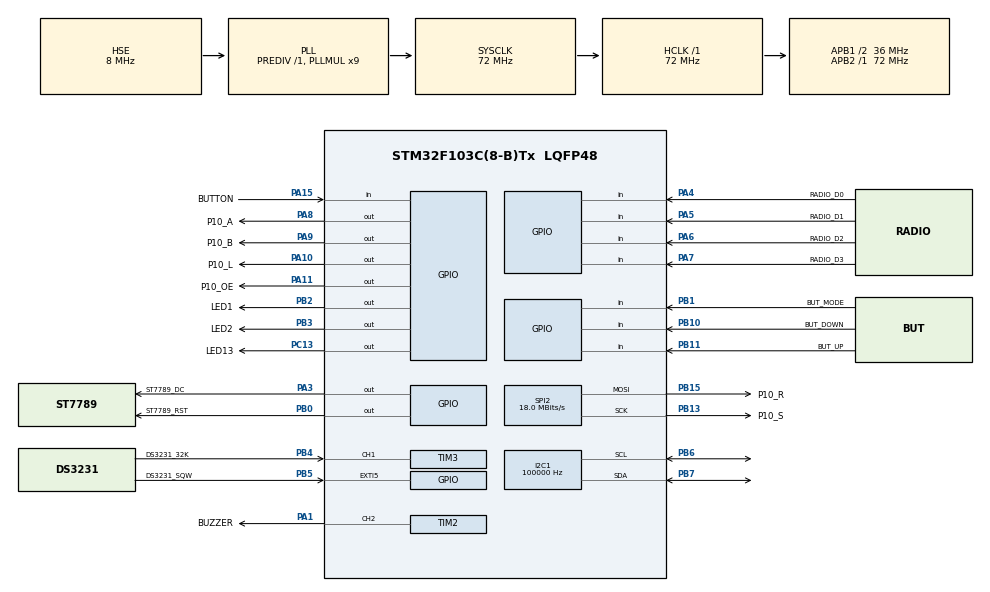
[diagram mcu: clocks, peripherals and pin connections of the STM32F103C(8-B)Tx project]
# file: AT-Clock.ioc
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Dma.Request0=SPI2_TX
Dma.SPI2_TX.0.Direction=DMA_MEMORY_TO_PERIPH
Dma.SPI2_TX.0.Instance=DMA1_Channel5
Dma.SPI2_TX.0.MemDataAlignment=DMA_MDATAALIGN_BYTE
Dma.SPI2_TX.0.MemInc=DMA_MINC_ENABLE
Dma.SPI2_TX.0.Mode=DMA_NORMAL
Dma.SPI2_TX.0.PeriphDataAlignment=DMA_PDATAALIGN_BYTE
Dma.SPI2_TX.0.PeriphInc=DMA_PINC_DISABLE
Dma.SPI2_TX.0.Priority=DMA_PRIORITY_LOW
I2C1.ClockSpeed=100000
I2C1.I2C_Mode=I2C_Standard
Mcu.Family=STM32F1
Mcu.Name=STM32F103C(8-B)Tx
Mcu.Package=LQFP48
NVIC.DMA1_Channel5_IRQn=true\:3\:0\:true\:false\:true\:false\:true\:true
NVIC.I2C1_ER_IRQn=true\:3\:0\:true\:false\:true\:true\:true\:true
NVIC.I2C1_EV_IRQn=true\:3\:0\:true\:false\:true\:true\:true\:true
NVIC.PriorityGroup=NVIC_PRIORITYGROUP_4
NVIC.TIM1_CC_IRQn=true\:2\:0\:true\:false\:true\:true\:true\:true
NVIC.TIM1_UP_IRQn=true\:2\:0\:true\:false\:true\:true\:true\:true
PA1.GPIO_Label=BUZZER
PA1.Signal=S_TIM2_CH2
PA10.GPIO_Label=P10_L
PA10.Signal=GPIO_Output
PA11.GPIO_Label=P10_OE
PA11.Signal=GPIO_Output
PA13.Mode=Serial_Wire
PA13.Signal=SYS_JTMS-SWDIO
PA14.Mode=Serial_Wire
PA14.Signal=SYS_JTCK-SWCLK
PA15.GPIO_Label=BUTTON
PA15.Signal=GPIO_Input
PA3.GPIO_Label=ST7789_DC
PA3.Signal=GPIO_Output
PA4.GPIO_Label=RADIO_D0
PA4.GPIO_PuPd=GPIO_PULLDOWN
PA4.Signal=GPIO_Input
PA5.GPIO_Label=RADIO_D1
PA5.GPIO_PuPd=GPIO_PULLDOWN
PA5.Signal=GPIO_Input
PA6.GPIO_Label=RADIO_D2
PA6.GPIO_PuPd=GPIO_PULLDOWN
PA6.Signal=GPIO_Input
PA7.GPIO_Label=RADIO_D3
PA7.GPIO_PuPd=GPIO_PULLDOWN
PA7.Signal=GPIO_Input
PA8.GPIO_Label=P10_A
PA8.Signal=GPIO_Output
PA9.GPIO_Label=P10_B
PA9.Signal=GPIO_Output
PB0.GPIO_Label=ST7789_RST
PB0.Signal=GPIO_Output
PB1.GPIO_Label=BUT_MODE
PB1.GPIO_PuPd=GPIO_PULLUP
PB1.Signal=GPIO_Input
PB10.GPIO_Label=BUT_DOWN
PB10.GPIO_PuPd=GPIO_PULLUP
PB10.Signal=GPIO_Input
PB11.GPIO_Label=BUT_UP
PB11.GPIO_PuPd=GPIO_PULLUP
PB11.Signal=GPIO_Input
PB13.GPIO_Label=P10_S
PB13.Mode=TX_Only_Simplex_Unidirect_Master
PB13.Signal=SPI2_SCK
PB15.GPIO_Label=P10_R
PB15.Mode=TX_Only_Simplex_Unidirect_Master
PB15.Signal=SPI2_MOSI
PB2.GPIO_Label=LED1
PB2.Signal=GPIO_Output
PB3.GPIO_Label=LED2
PB3.Signal=GPIO_Output
PB4.GPIO_Label=DS3231_32K
PB4.Signal=S_TIM3_CH1
PB5.GPIO_Label=DS3231_SQW
PB5.Signal=GPXTI5
PB6.GPIO_Pu=GPIO_PULLUP
PB6.Mode=I2C
PB6.Signal=I2C1_SCL
PB7.GPIO_Pu=GPIO_PULLUP
PB7.Mode=I2C
PB7.Signal=I2C1_SDA
PC13-TAMPER-RTC.GPIO_Label=LED13
PC13-TAMPER-RTC.Signal=GPIO_Output
PD0-OSC_IN.Mode=HSE-External-Oscillator
PD0-OSC_IN.Signal=RCC_OSC_IN
PD1-OSC_OUT.Mode=HSE-External-Oscillator
PD1-OSC_OUT.Signal=RCC_OSC_OUT
ProjectManager.HeapSize=0x200
ProjectManager.StackSize=0x400
ProjectManager.TargetToolchain=STM32CubeIDE
RCC.AHBFreq_Value=72000000
RCC.APB1CLKDivider=RCC_HCLK_DIV2
RCC.APB1Freq_Value=36000000
RCC.APB1TimFreq_Value=72000000
RCC.APB2Freq_Value=72000000
RCC.APB2TimFreq_Value=72000000
RCC.HCLKFreq_Value=72000000
RCC.PLLMUL=RCC_PLL_MUL9
RCC.PLLSourceVirtual=RCC_PLLSOURCE_HSE
RCC.SYSCLKFreq_VALUE=72000000
RCC.SYSCLKSource=RCC_SYSCLKSOURCE_PLLCLK
RCC.USBFreq_Value=72000000
SH.S_TIM2_CH2.0=TIM2_CH2,PWM Generation2 CH2
SH.S_TIM3_CH1.0=TIM3_CH1,Input_Capture1_from_TI1
SPI2.BaudRatePrescaler=SPI_BAUDRATEPRESCALER_2
SPI2.CLKPolarity=SPI_POLARITY_LOW
SPI2.CalculateBaudRate=18.0 MBits/s
SPI2.Direction=SPI_DIRECTION_2LINES
SPI2.Mode=SPI_MODE_MASTER
SPI2.VirtualType=VM_MASTER
TIM1.Channel-Output\ Compare1\ No\ Output=TIM_CHANNEL_1
TIM1.OCMode_1=TIM_OCMODE_ACTIVE
TIM1.Period=99
TIM1.Prescaler=500-1
TIM1.Pulse-Output\ Compare1\ No\ Output=10
TIM2.Channel-PWM\ Generation2\ CH2=TIM_CHANNEL_2
TIM2.Period=99
TIM2.Prescaler=365
TIM2.Pulse-PWM\ Generation2\ CH2=49
TIM3.Channel-Input_Capture1_from_TI1=TIM_CHANNEL_1
TIM3.Prescaler=327
VP_TIM1_VS_ClockSourceINT.Mode=Internal
VP_TIM1_VS_no_output1.Mode=Output Compare1 No Output
VP_TIM2_VS_ClockSourceINT.Mode=Internal
board=custom

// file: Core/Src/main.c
/* USER CODE BEGIN Header */
/**
  ******************************************************************************
  * @file           : main.c
  * @brief          : Main program body
  ******************************************************************************
  * @attention
  *
  * <h2><center>&copy; Copyright (c) 2020 STMicroelectronics.
  * All rights reserved.</center></h2>
  *
  * This software component is licensed by ST under BSD 3-Clause license,
  * the "License"; You may not use this file except in compliance with the
  * License. You may obtain a copy of the License at:
  *                        opensource.org/licenses/BSD-3-Clause
  *
  ******************************************************************************
  */
/* USER CODE END Header */
#include "main.h"

/* USER CODE BEGIN Includes */
#include <string.h>
#include "p10.h"
//#include "st7789.h"

/* USER CODE END Includes */

/* USER CODE BEGIN PD */
#define BUTTON_RANGE 2  //Set 5 for old buttons
#define RADIO_RANGE 5
#define BUTTON_REPEAT_DELAY 200
#define BUTTON_REPEAT_PERIOD 20
#define MODE_BRIGHTNESS 0
#define MODE_HOUR 1
#define MODE_MINUTE 2
#define MODE_SECOND 3
#define MODE_CNT 4
#define BUZZER_ON 1
//#define BUZZER_PRESCALER1 116
//#define BUZZER_PRESCALER2 110
//#define BUZZER_PRESCALER1 364
//#define BUZZER_PRESCALER2 305
#define BUZZER_PRESCALER1 233
#define BUZZER_PRESCALER2 221
#define BUZZER_PRESCALER_BUTTON 2000
#define SW_READY 0
#define SW_STARTED 1
#define SW_STOPPED 2

#define DEV_ADDR 0xD0

#define MAX(A,B) ((A) > (B) ? (A) : (B))
#define MIN(A,B) ((A) < (B) ? (A) : (B))

#define PROGRAM_CLOCK 0
#define PROGRAM_STOPWATCH 1
#define PROGRAM_TIMER3 2
#define PROGRAM_NUMBERS 3
#define PROGRAM_COUNT 4
#define PROGRAM_CNT 5

#define TIMER3_START -3*60*100

/* USER CODE END PD */

I2C_HandleTypeDef hi2c1;

SPI_HandleTypeDef hspi2;
DMA_HandleTypeDef hdma_spi2_tx;

TIM_HandleTypeDef htim1;
TIM_HandleTypeDef htim2;
TIM_HandleTypeDef htim3;

void SystemClock_Config(void);
static void MX_GPIO_Init(void);
static void MX_DMA_Init(void);
static void MX_I2C1_Init(void);
static void MX_SPI2_Init(void);
static void MX_TIM1_Init(void);
static void MX_TIM2_Init(void);
static void MX_TIM3_Init(void);
/* USER CODE BEGIN PFP */

//#define BRIGHTNESS_STEPS 10
//uint32_t brightness[] = {4, 12, 19, 24, 29, 36, 49, 64, 79, 99};
#define BRIGHTNESS_STEPS 13
uint32_t brightness[] = {1, 2, 4, 6, 9, 12, 16, 22, 29, 39, 54, 74, 99};
int brightness_index = 8;

#define SIGNAL_STEPS 13
int signals[] = {5, 10, 15, 20, 30, 45, 0, 60, 90, 120, 180, 240, 300};
int signal_index = 6;

void Test_P10();
/* USER CODE END PFP */

/* USER CODE BEGIN 0 */

int IntToBCD (int Value)
{
   return (((Value / 10) << 4) | (Value % 10));
}
int BCDToInt(int BCD)
{
   return (((BCD >> 4) * 10) + (BCD & 0xF));
}
int BCDTimeToInt(uint8_t *Time, int hs) {
  return 60*60*100 * BCDToInt(Time[2]) + 60*100 * BCDToInt(Time[1]) + 100 * BCDToInt(Time[0]) + hs;
}

/*
uint8_t p10_test[P10_BUF_SIZE] = {
    0b00110001, 0b10111101, 0b00101100, 0b00110001, 0b11010010, 0b10000001, 0b10000000, 0b00000000,
    0b01010010, 0b10100001, 0b00100010, 0b00000010, 0b00010010, 0b00000010, 0b10000000, 0b00000000,
    0b10010100, 0b10111001, 0b00100001, 0b01001010, 0b00010100, 0b10000100, 0b10000000, 0b00000000,
    0b10010100, 0b10100100, 0b11100111, 0b01001010, 0b00011000, 0b10000100, 0b10000000, 0b00000000,
    0b10010111, 0b10100100, 0b00100001, 0b00111010, 0b00010100, 0b10000111, 0b10000000, 0b00000000,
    0b10010100, 0b10100100, 0b00100010, 0b00001010, 0b00010010, 0b10000100, 0b10000000, 0b00000000,
    0b10010100, 0b10111000, 0b00101100, 0b00110001, 0b11010010, 0b10000100, 0b10100000, 0b00000000,
    0b00000000, 0b00000000, 0b00000000, 0b00000000, 0b00000000, 0b00000000, 0b00000000, 0b00000000,

    0b00000000, 0b00000000, 0b00000000, 0b00000000, 0b00000000, 0b00000000, 0b00000000, 0b00000000,
    0b00000000, 0b00000000, 0b00000000, 0b00000000, 0b00000010, 0b00001100, 0b11110001, 0b00101111,
    0b00000000, 0b00000000, 0b00000000, 0b00000000, 0b00000110, 0b00010010, 0b00010001, 0b00101000,
    0b00000000, 0b00000000, 0b00000000, 0b00000000, 0b00001010, 0b01000010, 0b01100101, 0b00101110,
    0b00000000, 0b00000000, 0b00000000, 0b00000000, 0b00000010, 0b00000100, 0b00010001, 0b11100001,
    0b00000000, 0b00000000, 0b00000000, 0b00000000, 0b00000010, 0b01001000, 0b00010100, 0b00100001,
    0b00000000, 0b00000000, 0b00000000, 0b00000000, 0b00000010, 0b00010000, 0b00010000, 0b00100001,
    0b00000000, 0b00000000, 0b00000000, 0b00000000, 0b00000010, 0b00011110, 0b11100000, 0b00101110
};
*/
/*
uint8_t p10_start[P10_BUF_SIZE] = {
    0b00111010, 0b00011100, 0b00111011, 0b11101110, 0b00110001, 0b10000000, 0b00000000, 0b00000000,
    0b01001010, 0b00010010, 0b01001000, 0b10001001, 0b01001010, 0b00000000, 0b00000000, 0b00000000,
    0b10001010, 0b00010010, 0b10001000, 0b10001001, 0b01001010, 0b00000000, 0b00000000, 0b00000000,
    0b10001010, 0b00011100, 0b10001000, 0b10001110, 0b01001001, 0b10000000, 0b00000000, 0b00000000,
    0b11111010, 0b00010010, 0b11111000, 0b10001001, 0b01001000, 0b01000000, 0b00000000, 0b00000000,
    0b10001010, 0b00010010, 0b10001000, 0b10001001, 0b01001000, 0b01000000, 0b00000000, 0b00000000,
    0b10001011, 0b11011100, 0b10001000, 0b10001001, 0b00110001, 0b10000000, 0b00000000, 0b00000000,
    0b00000000, 0b00000000, 0b00000000, 0b00000000, 0b00000000, 0b00000000, 0b00000000, 0b00000000,

    0b00000000, 0b00000000, 0b00000000, 0b00000000, 0b00000000, 0b00000000, 0b00000000, 0b00000000,
    0b00000000, 0b00000000, 0b00000000, 0b00000000, 0b00000111, 0b11010100, 0b01010100, 0b01001110,
    0b00000000, 0b00000000, 0b00000000, 0b00000000, 0b00000001, 0b00010110, 0b11010110, 0b01010000,
    0b00000000, 0b00000000, 0b00000000, 0b00000000, 0b00000001, 0b00010101, 0b01010101, 0b01010000,
    0b00000000, 0b00000000, 0b00000000, 0b00000000, 0b00000001, 0b00010100, 0b01010100, 0b11010000,
    0b00000000, 0b00000000, 0b00000000, 0b00000000, 0b00000001, 0b00010100, 0b01010100, 0b01010011,
    0b00000000, 0b00000000, 0b00000000, 0b00000000, 0b00000001, 0b00010100, 0b01010100, 0b01010001,
    0b00000000, 0b00000000, 0b00000000, 0b00000000, 0b00000001, 0b00010100, 0b01010100, 0b01001110,
};
*/
uint8_t p10_brightness[P10_BUF_SIZE] = {
    0b01110111, 0b00100100, 0b11000111, 0b01111101, 0b00000000, 0b00000000, 0b00000000, 0b00000000,
    0b10010100, 0b10100101, 0b00101000, 0b00010001, 0b00000000, 0b00000000, 0b00000000, 0b00000000,
    0b10010100, 0b10101001, 0b00101000, 0b00010001, 0b00000000, 0b00000000, 0b00000000, 0b00000000,
    0b01110111, 0b00110001, 0b00101000, 0b00010001, 0b11000000, 0b00000000, 0b00000000, 0b00000000,
    0b10010100, 0b00101001, 0b00101000, 0b00010001, 0b00100000, 0b00000000, 0b00000000, 0b00000000,
    0b10010100, 0b00100101, 0b00101000, 0b00010001, 0b00100000, 0b00000000, 0b00000000, 0b00000000,
    0b10010100, 0b00100100, 0b11000111, 0b00010001, 0b11000000, 0b00000000, 0b00000000, 0b00000000,
    0b00000000, 0b00000000, 0b00000000, 0b00000000, 0b00000000, 0b00000000, 0b00000000, 0b00000000,

    0b00100000, 0b00000000, 0b00000000, 0b00000000, 0b00000000, 0b00000000, 0b00000000, 0b00000000,
    0b00100000, 0b00000000, 0b00000000, 0b00000000, 0b00000000, 0b00000000, 0b00000000, 0b00000000,
    0b11111000, 0b00000000, 0b00000000, 0b00000000, 0b00000000, 0b00000000, 0b00000000, 0b00000000,
    0b00100000, 0b00000000, 0b00000000, 0b00000000, 0b00000000, 0b00000000, 0b00000000, 0b00000000,
    0b00100000, 0b00000000, 0b00000000, 0b00000000, 0b00000000, 0b00000000, 0b00000000, 0b00000000,
    0b00000000, 0b00000000, 0b00000000, 0b00000000, 0b00000000, 0b00000000, 0b00000000, 0b00000000,
    0b11111000, 0b00000000, 0b00000000, 0b00000000, 0b00000000, 0b00000000, 0b00000000, 0b00000000,
    0b00000000, 0b00000000, 0b00000000, 0b00000000, 0b00000000, 0b00000000, 0b00000000, 0b00000000,
};

uint8_t p10_program_clock[P10_BUF_SIZE] = {
    0b11100111, 0b10101010, 0b10001010, 0b00100000, 0b00000000, 0b00000000, 0b00000000, 0b00000000,
    0b10010100, 0b00101010, 0b10001011, 0b01100000, 0b00000000, 0b00000000, 0b00000000, 0b00000000,
    0b10010100, 0b00101010, 0b10001010, 0b10100000, 0b00000000, 0b00000000, 0b00000000, 0b00000000,
    0b11100111, 0b10011100, 0b10011010, 0b00100000, 0b00000000, 0b00000000, 0b00000000, 0b00000000,
    0b10000100, 0b00101010, 0b10101010, 0b00100000, 0b00000000, 0b00000000, 0b00000000, 0b00000000,
    0b10000100, 0b00101010, 0b11001010, 0b00100000, 0b00000000, 0b00000000, 0b00000000, 0b00000000,
    0b10000111, 0b10101010, 0b10001010, 0b00100000, 0b00000000, 0b00000000, 0b00000000, 0b00000000,
    0b00000000, 0b00000000, 0b00000000, 0b00000000, 0b00000000, 0b00000000, 0b00000000, 0b00000000,

    0b00100000, 0b00000000, 0b00000000, 0b00000000, 0b00000000, 0b00000000, 0b00000000, 0b00000000,
    0b01110000, 0b00000000, 0b00000000, 0b00000000, 0b00000000, 0b00010010, 0b00110011, 0b10100001,
    0b11111000, 0b00000000, 0b00000000, 0b00000000, 0b00000000, 0b00010010, 0b01010100, 0b00100001,
    0b00000000, 0b00000000, 0b00000000, 0b00000000, 0b00000000, 0b00010010, 0b10010100, 0b00100001,
    0b00000000, 0b00000000, 0b00000000, 0b00000000, 0b00000000, 0b00001110, 0b10010100, 0b00111001,
    0b11111000, 0b00000000, 0b00000000, 0b00000000, 0b00000000, 0b00000010, 0b11110100, 0b00100101,
    0b01110000, 0b00000000, 0b00000000, 0b00000000, 0b00000000, 0b00000010, 0b10010100, 0b00100101,
    0b00100000, 0b00000000, 0b00000000, 0b00000000, 0b00000000, 0b00000010, 0b10010011, 0b10111001,
};

uint8_t p10_program_stopwatch[P10_BUF_SIZE] = {
    0b11100111, 0b10101010, 0b10001010, 0b00100000, 0b00000000, 0b00000000, 0b00000000, 0b00000000,
    0b10010100, 0b00101010, 0b10001011, 0b01100000, 0b00000000, 0b00000000, 0b00000000, 0b00000000,
    0b10010100, 0b00101010, 0b10001010, 0b10100000, 0b00000000, 0b00000000, 0b00000000, 0b00000000,
    0b11100111, 0b10011100, 0b10011010, 0b00100000, 0b00000000, 0b00000000, 0b00000000, 0b00000000,
    0b10000100, 0b00101010, 0b10101010, 0b00100000, 0b00000000, 0b00000000, 0b00000000, 0b00000000,
    0b10000100, 0b00101010, 0b11001010, 0b00100000, 0b00000000, 0b00000000, 0b00000000, 0b00000000,
    0b10000111, 0b10101010, 0b10001010, 0b00100000, 0b00000000, 0b00000000, 0b00000000, 0b00000000,
    0b00000000, 0b00000000, 0b00000000, 0b00000000, 0b00000000, 0b00000000, 0b00000000, 0b00000000,

    0b00100000, 0b00000000, 0b00000000, 0b00000000, 0b00000000, 0b00000000, 0b00000000, 0b00000000,
    0b01110000, 0b00000011, 0b10111101, 0b00101001, 0b01001000, 0b11000110, 0b01000101, 0b11101110,
    0b11111000, 0b00000100, 0b00100001, 0b00101001, 0b01001001, 0b01001001, 0b01101101, 0b00001001,
    0b00000000, 0b00000100, 0b00100001, 0b01001001, 0b01001001, 0b01001001, 0b01010101, 0b00001001,
    0b00000000, 0b00000100, 0b00111101, 0b10000111, 0b01111001, 0b01001001, 0b01000101, 0b11101110,
    0b11111000, 0b00000100, 0b00100001, 0b01000001, 0b01001001, 0b01001001, 0b01000101, 0b00001000,
    0b01110000, 0b00000100, 0b00100001, 0b00100001, 0b01001011, 0b11101001, 0b01000101, 0b00001000,
    0b00100000, 0b00000011, 0b10111101, 0b00100110, 0b01001010, 0b00100110, 0b01000101, 0b11101000,
};

uint8_t p10_program_timer3[P10_BUF_SIZE] = {
    0b11100111, 0b10101010, 0b10001010, 0b00100000, 0b00000000, 0b00000000, 0b00000000, 0b00000000,
    0b10010100, 0b00101010, 0b10001011, 0b01100000, 0b00000000, 0b00000000, 0b00000000, 0b00000000,
    0b10010100, 0b00101010, 0b10001010, 0b10100000, 0b00000000, 0b00000000, 0b00000000, 0b00000000,
    0b11100111, 0b10011100, 0b10011010, 0b00100000, 0b00000000, 0b00000000, 0b00000000, 0b00000000,
    0b10000100, 0b00101010, 0b10101010, 0b00100000, 0b00000000, 0b00000000, 0b00000000, 0b00000000,
    0b10000100, 0b00101010, 0b11001010, 0b00100000, 0b00000000, 0b00000000, 0b00000000, 0b00000000,
    0b10000111, 0b10101010, 0b10001010, 0b00100000, 0b00000000, 0b00000000, 0b00000000, 0b00000000,
    0b00000000, 0b00000000, 0b00000000, 0b00000000, 0b00000000, 0b00000000, 0b00000000, 0b00000000,

    0b00100000, 0b00000000, 0b00000000, 0b00000000, 0b00000000, 0b00000000, 0b00000000, 0b00000000,
    0b01110000, 0b00000000, 0b00000000, 0b00000000, 0b11111000, 0b11001110, 0b01000101, 0b11101110,
    0b11111000, 0b00000000, 0b00000000, 0b00000000, 0b00100001, 0b01000000, 0b01101101, 0b00001001,
    0b00000000, 0b00000000, 0b00000000, 0b00000000, 0b00100010, 0b01010001, 0b01010101, 0b00001001,
    0b00000000, 0b00000000, 0b00000000, 0b00000000, 0b00100010, 0b01010011, 0b01000101, 0b11101110,
    0b11111000, 0b00000000, 0b00000000, 0b00000000, 0b00100011, 0b11010101, 0b01000101, 0b00001000,
    0b01110000, 0b00000000, 0b00000000, 0b00000000, 0b00100010, 0b01011001, 0b01000101, 0b00001000,
    0b00100000, 0b00000000, 0b00000000, 0b00000000, 0b00100010, 0b01010001, 0b01000101, 0b11101000,
};

uint8_t p10_program_numbers[P10_BUF_SIZE] = {
    0b11100111, 0b10101010, 0b10001010, 0b00100000, 0b00000000, 0b00000000, 0b00000000, 0b00000000,
    0b10010100, 0b00101010, 0b10001011, 0b01100000, 0b00000000, 0b00000000, 0b00000000, 0b00000000,
    0b10010100, 0b00101010, 0b10001010, 0b10100000, 0b00000000, 0b00000000, 0b00000000, 0b00000000,
    0b11100111, 0b10011100, 0b10011010, 0b00100000, 0b00000000, 0b00000000, 0b00000000, 0b00000000,
    0b10000100, 0b00101010, 0b10101010, 0b00100000, 0b00000000, 0b00000000, 0b00000000, 0b00000000,
    0b10000100, 0b00101010, 0b11001010, 0b00100000, 0b00000000, 0b00000000, 0b00000000, 0b00000000,
    0b10000111, 0b10101010, 0b10001010, 0b00100000, 0b00000000, 0b00000000, 0b00000000, 0b00000000,
    0b00000000, 0b00000000, 0b00000000, 0b00000000, 0b00000000, 0b00000000, 0b00000000, 0b00000000,

    0b00100000, 0b00000000, 0b00000000, 0b00000000, 0b00000000, 0b00000000, 0b00000000, 0b00000000,
    0b01110000, 0b00000001, 0b11100110, 0b00001001, 0b00110010, 0b00101111, 0b01110000, 0b11010001,
    0b11111000, 0b00000001, 0b00101001, 0b00001001, 0b01001011, 0b01101000, 0b01001001, 0b01011011,
    0b00000000, 0b00000001, 0b00101001, 0b00001001, 0b01001010, 0b10101000, 0b01001010, 0b01010101,
    0b00000000, 0b00000001, 0b00101001, 0b00001111, 0b01001010, 0b00101111, 0b01110010, 0b01010001,
    0b11111000, 0b00000001, 0b00101001, 0b00001001, 0b01001010, 0b00101000, 0b01000011, 0b11010001,
    0b01110000, 0b00000001, 0b00101001, 0b00001001, 0b01001010, 0b00101000, 0b01000010, 0b01010001,
    0b00100000, 0b00000001, 0b00100110, 0b00001001, 0b00110010, 0b00101111, 0b01000010, 0b01010001,
};

uint8_t p10_program_count[P10_BUF_SIZE] = {
    0b11100111, 0b10101010, 0b10001010, 0b00100000, 0b00000000, 0b00000000, 0b00000000, 0b00000000,
    0b10010100, 0b00101010, 0b10001011, 0b01100000, 0b00000000, 0b00000000, 0b00000000, 0b00000000,
    0b10010100, 0b00101010, 0b10001010, 0b10100000, 0b00000000, 0b00000000, 0b00000000, 0b00000000,
    0b11100111, 0b10011100, 0b10011010, 0b00100000, 0b00000000, 0b00000000, 0b00000000, 0b00000000,
    0b10000100, 0b00101010, 0b10101010, 0b00100000, 0b00000000, 0b00000000, 0b00000000, 0b00000000,
    0b10000100, 0b00101010, 0b11001010, 0b00100000, 0b00000000, 0b00000000, 0b00000000, 0b00000000,
    0b10000111, 0b10101010, 0b10001010, 0b00100000, 0b00000000, 0b00000000, 0b00000000, 0b00000000,
    0b00000000, 0b00000000, 0b00000000, 0b00000000, 0b00000000, 0b00000000, 0b00000000, 0b00000000,

    0b00100000, 0b00000000, 0b00000000, 0b00000000, 0b00000000, 0b00000000, 0b00000000, 0b00000000,
    0b01110000, 0b00000000, 0b01110100, 0b10111101, 0b11110000, 0b00100010, 0b11110111, 0b00100001,
    0b11111000, 0b00000000, 0b10000100, 0b10100000, 0b01000000, 0b00100010, 0b10000100, 0b10100001,
    0b00000000, 0b00000000, 0b10000100, 0b10100000, 0b01000000, 0b00100010, 0b10000100, 0b10100001,
    0b00000000, 0b00000000, 0b10000011, 0b10111100, 0b01000000, 0b00100110, 0b10000111, 0b00111001,
    0b11111000, 0b00000000, 0b10000000, 0b10100000, 0b01000000, 0b00101010, 0b10000100, 0b00100101,
    0b01110000, 0b00000000, 0b10000000, 0b10100000, 0b01000000, 0b00110010, 0b10000100, 0b00100101,
    0b00100000, 0b00000000, 0b01110000, 0b10111100, 0b01000000, 0b00100010, 0b10000100, 0b00111001,
};

uint8_t p10_signal[P10_BUF_SIZE] = {
    0b01110100, 0b10111101, 0b00100011, 0b00011000, 0b00000000, 0b00000000, 0b00000000, 0b00000000,
    0b10000100, 0b10100001, 0b00100101, 0b00101000, 0b00000000, 0b00000000, 0b00000000, 0b00000000,
    0b10000100, 0b10100001, 0b00101001, 0b01001000, 0b00000000, 0b00000000, 0b00000000, 0b00000000,
    0b10000100, 0b10100001, 0b11101001, 0b01001000, 0b00000000, 0b00000000, 0b00000000, 0b00000000,
    0b10000101, 0b10100001, 0b00101111, 0b01001000, 0b00000000, 0b00000000, 0b00000000, 0b00000000,
    0b10000110, 0b10100001, 0b00101001, 0b01001000, 0b00000000, 0b00000000, 0b00000000, 0b00000000,
    0b01110100, 0b10100001, 0b00101001, 0b01001000, 0b00000000, 0b00000000, 0b00000000, 0b00000000,
    0b00000000, 0b00000000, 0b00000000, 0b00000000, 0b00000000, 0b00000000, 0b00000000, 0b00000000,

    0b00100000, 0b00000000, 0b00000000, 0b00000000, 0b00000000, 0b00000000, 0b00000000, 0b00000000,
    0b00100000, 0b00000000, 0b00000000, 0b00000000, 0b00000000, 0b00000000, 0b01001011, 0b11011111,
    0b11111000, 0b00000000, 0b00000000, 0b00000000, 0b00000000, 0b00000000, 0b01001010, 0b00000100,
    0b00100000, 0b00000000, 0b00000000, 0b00000000, 0b00000000, 0b00000000, 0b01001010, 0b00000100,
    0b00100000, 0b00000000, 0b00000000, 0b00000000, 0b00000000, 0b00000000, 0b01111011, 0b11100100,
    0b00000000, 0b00000000, 0b00000000, 0b00000000, 0b00000000, 0b00000000, 0b01001010, 0b00000100,
    0b11111000, 0b00000000, 0b00000000, 0b00000000, 0b00000000, 0b00000000, 0b01001010, 0b00000100,
    0b00000000, 0b00000000, 0b00000000, 0b00000000, 0b00000000, 0b00000000, 0b01001011, 0b11100100,
};

uint8_t p10_timer3_setup[P10_BUF_SIZE] = {
    0b01110111, 0b11000110, 0b11100111, 0b11000000, 0b00000000, 0b00000000, 0b00000000, 0b00000000,
    0b10000001, 0b00001010, 0b10010001, 0b00010000, 0b00000000, 0b00000000, 0b00000000, 0b00000000,
    0b10000001, 0b00010010, 0b10010001, 0b00000000, 0b00000000, 0b00000000, 0b00000000, 0b00000000,
    0b10000001, 0b00010010, 0b11100001, 0b00000000, 0b00000000, 0b00000000, 0b00000000, 0b00000000,
    0b10000001, 0b00011110, 0b10000001, 0b00000000, 0b00000000, 0b00000000, 0b00000000, 0b00000000,
    0b10000001, 0b00010010, 0b10000001, 0b00010000, 0b00000000, 0b00000000, 0b00000000, 0b00000000,
    0b01110001, 0b00010010, 0b10000001, 0b00000000, 0b00000000, 0b00000000, 0b00000000, 0b00000000,
    0b00000000, 0b00000000, 0b00000000, 0b00000000, 0b00000000, 0b00000000, 0b00000000, 0b00000000,

    0b00000000, 0b00000000, 0b00000000, 0b00000000, 0b00000000, 0b00000000, 0b00000000, 0b00000000,
    0b00000000, 0b00000000, 0b00000000, 0b00000000, 0b00000000, 0b00000000, 0b00000000, 0b00000000,
    0b00000000, 0b00000000, 0b00000000, 0b00000000, 0b00000000, 0b00000000, 0b00000000, 0b00000000,
    0b00000000, 0b00000000, 0b00000000, 0b00000000, 0b00000000, 0b00000000, 0b00000000, 0b00000000,
    0b00000000, 0b00000000, 0b00000000, 0b00000000, 0b00000000, 0b00000000, 0b00000000, 0b00000000,
    0b00000000, 0b00000000, 0b00000000, 0b00000000, 0b00000000, 0b00000000, 0b00000000, 0b00000000,
    0b00000000, 0b00000000, 0b00000000, 0b00000000, 0b00000000, 0b00000000, 0b00000000, 0b00000000,
    0b00000000, 0b00000000, 0b00000000, 0b00000000, 0b00000000, 0b00000000, 0b00000000, 0b00000000,
};

uint8_t p10_stopwatch_sound0[P10_BUF_SIZE] = {
    0b11100111, 0b00100101, 0b00010000, 0b00000000, 0b00000000, 0b00000000, 0b00000000, 0b00000000,
    0b00010100, 0b10100101, 0b00100000, 0b00000000, 0b00000000, 0b00000000, 0b00000000, 0b00000000,
    0b00010100, 0b10100101, 0b01000000, 0b00000000, 0b00000000, 0b00000000, 0b00000000, 0b00000000,
    0b01100111, 0b00011101, 0b10000000, 0b00000000, 0b00000000, 0b00000000, 0b00000000, 0b00000000,
    0b00010100, 0b10000101, 0b01000000, 0b00000000, 0b00000000, 0b00000000, 0b00000000, 0b00000000,
    0b00010100, 0b10000101, 0b00100000, 0b00000000, 0b00000000, 0b00000000, 0b00000000, 0b00000000,
    0b11100111, 0b00011001, 0b00010000, 0b00000000, 0b00000000, 0b00000000, 0b00000000, 0b00000000,
    0b00000000, 0b00000000, 0b00000000, 0b00000000, 0b00000000, 0b00000000, 0b00000000, 0b00000000,

    0b00100000, 0b00000000, 0b00000000, 0b00000000, 0b00000000, 0b00000000, 0b00000000, 0b00000000,
    0b01110000, 0b00000000, 0b00000000, 0b00000000, 0b00000000, 0b00000000, 0b01001011, 0b11011111,
    0b11111000, 0b00000000, 0b00000000, 0b00000000, 0b00000000, 0b00000000, 0b01001010, 0b00000100,
    0b00000000, 0b00000000, 0b00000000, 0b00000000, 0b00000000, 0b00000000, 0b01001010, 0b00000100,
    0b00000000, 0b00000000, 0b00000000, 0b00000000, 0b00000000, 0b00000000, 0b01111011, 0b11100100,
    0b11111000, 0b00000000, 0b00000000, 0b00000000, 0b00000000, 0b00000000, 0b01001010, 0b00000100,
    0b01110000, 0b00000000, 0b00000000, 0b00000000, 0b00000000, 0b00000000, 0b01001010, 0b00000100,
    0b00100000, 0b00000000, 0b00000000, 0b00000000, 0b00000000, 0b00000000, 0b01001011, 0b11100100,
};

uint8_t p10_stopwatch_sound1[P10_BUF_SIZE] = {
    0b11100111, 0b00100101, 0b00010000, 0b00000000, 0b00000000, 0b00000000, 0b00000000, 0b00000000,
    0b00010100, 0b10100101, 0b00100000, 0b00000000, 0b00000000, 0b00000000, 0b00000000, 0b00000000,
    0b00010100, 0b10100101, 0b01000000, 0b00000000, 0b00000000, 0b00000000, 0b00000000, 0b00000000,
    0b01100111, 0b00011101, 0b10000000, 0b00000000, 0b00000000, 0b00000000, 0b00000000, 0b00000000,
    0b00010100, 0b10000101, 0b01000000, 0b00000000, 0b00000000, 0b00000000, 0b00000000, 0b00000000,
    0b00010100, 0b10000101, 0b00100000, 0b00000000, 0b00000000, 0b00000000, 0b00000000, 0b00000000,
    0b11100111, 0b00011001, 0b00010000, 0b00000000, 0b00000000, 0b00000000, 0b00000000, 0b00000000,
    0b00000000, 0b00000000, 0b00000000, 0b00000000, 0b00000000, 0b00000000, 0b00000000, 0b00000000,

    0b00100000, 0b00000000, 0b00000000, 0b00000000, 0b00000000, 0b00000000, 0b00000000, 0b00000000,
    0b01110000, 0b00000000, 0b00000000, 0b00000000, 0b00000000, 0b00001111, 0b00111011, 0b11101000,
    0b11111000, 0b00000000, 0b00000000, 0b00000000, 0b00000000, 0b00001000, 0b01000000, 0b10001000,
    0b00000000, 0b00000000, 0b00000000, 0b00000000, 0b00000000, 0b00001000, 0b01000000, 0b10001000,
    0b00000000, 0b00000000, 0b00000000, 0b00000000, 0b00000000, 0b00001111, 0b01000000, 0b10001110,
    0b11111000, 0b00000000, 0b00000000, 0b00000000, 0b00000000, 0b00001000, 0b01000000, 0b10001001,
    0b01110000, 0b00000000, 0b00000000, 0b00000000, 0b00000000, 0b00001000, 0b01000000, 0b10001001,
    0b00100000, 0b00000000, 0b00000000, 0b00000000, 0b00000000, 0b00001111, 0b00111000, 0b10001110,
};

uint8_t p10_stopwatch_start0[P10_BUF_SIZE] = {
    0b11100111, 0b10101010, 0b10001010, 0b00100000, 0b11101111, 0b10001101, 0b11001111, 0b10001100,
    0b10010100, 0b00101010, 0b10001011, 0b01100001, 0b00000010, 0b00010101, 0b00100010, 0b00010101,
    0b10010100, 0b00011100, 0b10001010, 0b10100001, 0b00000010, 0b00100101, 0b00100010, 0b00100100,
    0b11100111, 0b10001000, 0b10011010, 0b00100001, 0b00000010, 0b00100101, 0b11000010, 0b00100100,
    0b10000100, 0b00011100, 0b10101010, 0b00100001, 0b00000010, 0b00111101, 0b00000010, 0b00111100,
    0b10000100, 0b00101010, 0b11001010, 0b00100001, 0b00000010, 0b00100101, 0b00000010, 0b00100101,
    0b10000111, 0b10101010, 0b10001010, 0b00100000, 0b11100010, 0b00100101, 0b00000010, 0b00100100,
    0b00000000, 0b00000000, 0b00000000, 0b00000000, 0b00000000, 0b00000000, 0b00000000, 0b00000000,

    0b00100000, 0b00000000, 0b00000000, 0b00000000, 0b00000000, 0b00000000, 0b00000000, 0b00000000,
    0b01110000, 0b00011101, 0b11101110, 0b00110001, 0b11000001, 0b11011111, 0b00011011, 0b10011111,
    0b11111000, 0b00100001, 0b00001001, 0b01001010, 0b00000010, 0b00000100, 0b00101010, 0b01000100,
    0b00000000, 0b00100001, 0b00001001, 0b01001010, 0b00000010, 0b00000100, 0b01001010, 0b01000100,
    0b00000000, 0b00100001, 0b11001110, 0b01001010, 0b00011010, 0b00000100, 0b01001011, 0b10000100,
    0b11111000, 0b00100001, 0b00101000, 0b01001010, 0b00000010, 0b00000100, 0b01111010, 0b00000100,
    0b01110000, 0b00100001, 0b00101000, 0b01001010, 0b00000010, 0b00000100, 0b01001010, 0b00000100,
    0b00100000, 0b00011101, 0b11001000, 0b00110001, 0b11000001, 0b11000100, 0b01001010, 0b00000100,
};

uint8_t p10_stopwatch_start1[P10_BUF_SIZE] = {
    0b11100111, 0b10101010, 0b10001010, 0b00100000, 0b11101111, 0b10001101, 0b11001111, 0b10001100,
    0b10010100, 0b00101010, 0b10001011, 0b01100001, 0b00000010, 0b00010101, 0b00100010, 0b00010101,
    0b10010100, 0b00011100, 0b10001010, 0b10100001, 0b00000010, 0b00100101, 0b00100010, 0b00100100,
    0b11100111, 0b10001000, 0b10011010, 0b00100001, 0b00000010, 0b00100101, 0b11000010, 0b00100100,
    0b10000100, 0b00011100, 0b10101010, 0b00100001, 0b00000010, 0b00111101, 0b00000010, 0b00111100,
    0b10000100, 0b00101010, 0b11001010, 0b00100001, 0b00000010, 0b00100101, 0b00000010, 0b00100101,
    0b10000111, 0b10101010, 0b10001010, 0b00100000, 0b11100010, 0b00100101, 0b00000010, 0b00100100,
    0b00000000, 0b00000000, 0b00000000, 0b00000000, 0b00000000, 0b00000000, 0b00000000, 0b00000000,

    0b00100000, 0b00000000, 0b00000000, 0b00000000, 0b00000000, 0b00000000, 0b00000000, 0b00000000,
    0b01110000, 0b00011110, 0b01100000, 0b01100111, 0b11010101, 0b00011011, 0b11101000, 0b10100110,
    0b11111000, 0b00010010, 0b10010000, 0b10010001, 0b00010101, 0b00101000, 0b10001000, 0b10101001,
    0b00000000, 0b00010010, 0b10010000, 0b10010001, 0b00010101, 0b01001000, 0b10001000, 0b10101001,
    0b00000000, 0b00010010, 0b10010000, 0b10010001, 0b00001110, 0b01001000, 0b10001001, 0b10111001,
    0b11111000, 0b00010010, 0b10010000, 0b10010001, 0b00010101, 0b01111000, 0b10001010, 0b10101001,
    0b01110000, 0b00010010, 0b10010000, 0b10010001, 0b00010101, 0b01001000, 0b10001100, 0b10101001,
    0b00100000, 0b00010010, 0b01100000, 0b01100001, 0b00010101, 0b01001000, 0b10001000, 0b10100110,
};

uint8_t p10_stopwatch_start2[P10_BUF_SIZE] = {
    0b11100111, 0b10101010, 0b10001010, 0b00100000, 0b11101111, 0b10001101, 0b11001111, 0b10001100,
    0b10010100, 0b00101010, 0b10001011, 0b01100001, 0b00000010, 0b00010101, 0b00100010, 0b00010101,
    0b10010100, 0b00011100, 0b10001010, 0b10100001, 0b00000010, 0b00100101, 0b00100010, 0b00100100,
    0b11100111, 0b10001000, 0b10011010, 0b00100001, 0b00000010, 0b00100101, 0b11000010, 0b00100100,
    0b10000100, 0b00011100, 0b10101010, 0b00100001, 0b00000010, 0b00111101, 0b00000010, 0b00111100,
    0b10000100, 0b00101010, 0b11001010, 0b00100001, 0b00000010, 0b00100101, 0b00000010, 0b00100101,
    0b10000111, 0b10101010, 0b10001010, 0b00100000, 0b11100010, 0b00100101, 0b00000010, 0b00100100,
    0b00000000, 0b00000000, 0b00000000, 0b00000000, 0b00000000, 0b00000000, 0b00000000, 0b00000000,

    0b00100000, 0b00000000, 0b00000000, 0b00000000, 0b00000000, 0b00000000, 0b00000000, 0b00000000,
    0b01110000, 0b00111100, 0b01101001, 0b01110000, 0b11000001, 0b11011111, 0b00011011, 0b10011111,
    0b11111000, 0b00100100, 0b10101001, 0b00001001, 0b01000010, 0b00000100, 0b00101010, 0b01000100,
    0b00000000, 0b00100101, 0b00101001, 0b00001010, 0b01000010, 0b00000100, 0b01001010, 0b01000100,
    0b00000000, 0b00100101, 0b00100111, 0b00110010, 0b01011010, 0b00000100, 0b01001011, 0b10000100,
    0b11111000, 0b00100101, 0b11100001, 0b00001011, 0b11000010, 0b00000100, 0b01111010, 0b00000100,
    0b01110000, 0b00100101, 0b00100001, 0b00001010, 0b01000010, 0b00000100, 0b01001010, 0b00000100,
    0b00100000, 0b00100101, 0b00101110, 0b01110010, 0b01000001, 0b11000100, 0b01001010, 0b00000100,
};

uint8_t p10_stopwatch_start3[P10_BUF_SIZE] = {
    0b11100111, 0b10101010, 0b10001010, 0b00100000, 0b11101111, 0b10001101, 0b11001111, 0b10001100,
    0b10010100, 0b00101010, 0b10001011, 0b01100001, 0b00000010, 0b00010101, 0b00100010, 0b00010101,
    0b10010100, 0b00011100, 0b10001010, 0b10100001, 0b00000010, 0b00100101, 0b00100010, 0b00100100,
    0b11100111, 0b10001000, 0b10011010, 0b00100001, 0b00000010, 0b00100101, 0b11000010, 0b00100100,
    0b10000100, 0b00011100, 0b10101010, 0b00100001, 0b00000010, 0b00111101, 0b00000010, 0b00111100,
    0b10000100, 0b00101010, 0b11001010, 0b00100001, 0b00000010, 0b00100101, 0b00000010, 0b00100101,
    0b10000111, 0b10101010, 0b10001010, 0b00100000, 0b11100010, 0b00100101, 0b00000010, 0b00100100,
    0b00000000, 0b00000000, 0b00000000, 0b00000000, 0b00000000, 0b00000000, 0b00000000, 0b00000000,

    0b00100000, 0b00000000, 0b00000000, 0b00000000, 0b00000000, 0b00000000, 0b00000000, 0b00000000,
    0b01110000, 0b01110111, 0b10001101, 0b00010111, 0b11000001, 0b11011111, 0b00011011, 0b10011111,
    0b11111000, 0b10000100, 0b10010101, 0b00010001, 0b00000010, 0b00000100, 0b00101010, 0b01000100,
    0b00000000, 0b10000100, 0b10100101, 0b00010001, 0b00000010, 0b00000100, 0b01001010, 0b01000100,
    0b00000000, 0b10000100, 0b10100101, 0b00110001, 0b00011010, 0b00000100, 0b01001011, 0b10000100,
    0b11111000, 0b10000100, 0b10100101, 0b01010001, 0b00000010, 0b00000100, 0b01111010, 0b00000100,
    0b01110000, 0b10000100, 0b10100101, 0b10010001, 0b00000010, 0b00000100, 0b01001010, 0b00000100,
    0b00100000, 0b01110100, 0b10100101, 0b00010001, 0b00000001, 0b11000100, 0b01001010, 0b00000100,
};

uint8_t p10_stopwatch_precision[P10_BUF_SIZE] = {
    0b11111001, 0b10010010, 0b10010011, 0b00011101, 0b11110100, 0b00000000, 0b00000000, 0b00000000,
    0b00100010, 0b01010010, 0b10010100, 0b10100000, 0b01000100, 0b00000000, 0b00000000, 0b00000000,
    0b00100010, 0b01010010, 0b10010100, 0b10100000, 0b01000100, 0b00000000, 0b00000000, 0b00000000,
    0b00100010, 0b01001110, 0b11110100, 0b10100000, 0b01000111, 0b00000000, 0b00000000, 0b00000000,
    0b00100010, 0b01000010, 0b10010100, 0b10100000, 0b01000100, 0b10000000, 0b00000000, 0b00000000,
    0b00100010, 0b01000010, 0b10010100, 0b10100000, 0b01000100, 0b10000000, 0b00000000, 0b00000000,
    0b00100001, 0b10000010, 0b10010011, 0b00011100, 0b01000111, 0b00000000, 0b00000000, 0b00000000,
    0b00000000, 0b00000000, 0b00000000, 0b00000000, 0b00000000, 0b00000000, 0b00000000, 0b00000000,

    0b00100000, 0b00000000, 0b00000000, 0b00000000, 0b00000000, 0b00000000, 0b00000000, 0b00000000,
    0b01110000, 0b00000000, 0b00000000, 0b00000000, 0b00000000, 0b00000000, 0b00000000, 0b00000000,
    0b11111000, 0b00000000, 0b00000000, 0b00000000, 0b00000000, 0b00000000, 0b00000000, 0b00000000,
    0b00000000, 0b00000000, 0b00000000, 0b00000000, 0b00000000, 0b00000000, 0b00000000, 0b00000000,
    0b00000000, 0b00000000, 0b00000000, 0b00000000, 0b00000000, 0b00000000, 0b00000000, 0b00000000,
    0b11111000, 0b00000000, 0b00000000, 0b00000000, 0b00000000, 0b00000000, 0b00000000, 0b00000000,
    0b01110000, 0b00000000, 0b00000000, 0b00000000, 0b00000000, 0b00000000, 0b00000000, 0b00000000,
    0b00100000, 0b00000000, 0b00000000, 0b00000000, 0b00000000, 0b00000000, 0b00000000, 0b00000000,
};

uint8_t p10_sprite1[6] = {
    0b00110000,
    0b01001000,
    0b10000100,
    0b10000100,
    0b01001000,
    0b00110000,
};
uint8_t p10_sprite2[6] = {
    0b00110000,
    0b01111000,
    0b11111100,
    0b11111100,
    0b01111000,
    0b00110000,
};
uint8_t p10_sprite_start[7*4] = {
    0b01110111, 0b11000110, 0b11100111, 0b11000000,
    0b10000001, 0b00001010, 0b10010001, 0b00000000,
    0b10000001, 0b00010010, 0b10010001, 0b00000000,
    0b01100001, 0b00010010, 0b11100001, 0b00000000,
    0b00010001, 0b00011110, 0b10010001, 0b00000000,
    0b00010001, 0b00010010, 0b10010001, 0b00000000,
    0b11100001, 0b00010010, 0b10010001, 0b00000000,
};

void p10_test_text()
{
//  p10_putscreen(p10_test);
  HAL_Delay(10000);
  p10_putrect(0, 0, 64, 16, 0);
}

void p10_zero()
{
  p10_putrect(0, 0, 64, 16, 0);
  p10_putnumber(10, 0, 0);
  p10_putnumber(23, 0, 0);
  p10_putnumber(33, 0, 0);
  p10_putnumber(46, 0, 0);
  p10_putrect(19, 4, 3, 2, 1);
  p10_putrect(19, 10, 3, 2, 1);
  p10_putrect(42, 14, 3, 2, 1);
}

int button_mode = -BUTTON_RANGE;
int button_up = -BUTTON_RANGE;
int button_down = -BUTTON_RANGE;
int radio_a = -RADIO_RANGE;
int radio_b = -RADIO_RANGE;
int radio_c = -RADIO_RANGE;
int radio_d = -RADIO_RANGE;
int button_mode_repeat = BUTTON_REPEAT_DELAY;
int button_up_repeat = BUTTON_REPEAT_DELAY;
int button_down_repeat = BUTTON_REPEAT_DELAY;
int radio_a_repeat = BUTTON_REPEAT_DELAY;
int radio_b_repeat = BUTTON_REPEAT_DELAY;
int radio_c_repeat = BUTTON_REPEAT_DELAY;
int radio_d_repeat = BUTTON_REPEAT_DELAY;
int button_mode_pressed = 0;
int button_mode_unpressed = 0;
int button_mode_repeated = 0;
int button_mode_hold = 0;
int button_up_pressed = 0;
int button_up_unpressed = 0;
int button_up_repeated = 0;
int button_up_hold = 0;
int button_down_pressed = 0;
int button_down_unpressed = 0;
int button_down_repeated = 0;
int button_down_hold = 0;
int radio_a_pressed = 0;
int radio_a_unpressed = 0;
int radio_a_repeated = 0;
int radio_a_hold = 0;
int radio_b_pressed = 0;
int radio_b_unpressed = 0;
int radio_b_repeated = 0;
int radio_b_hold = 0;
int radio_c_pressed = 0;
int radio_c_unpressed = 0;
int radio_c_repeated = 0;
int radio_c_hold = 0;
int radio_d_pressed = 0;
int radio_d_unpressed = 0;
int radio_d_repeated = 0;
int radio_d_hold = 0;

void button_filter() {
  //Фільтр кнопак
  button_mode_pressed = 0;
  button_mode_unpressed = 0;
  button_mode_repeated = 0;
  button_up_pressed = 0;
  button_up_unpressed = 0;
  button_up_repeated = 0;
  button_down_pressed = 0;
  button_down_unpressed = 0;
  button_down_repeated = 0;
  radio_a_pressed = 0;
  radio_a_unpressed = 0;
  radio_a_repeated = 0;
  radio_b_pressed = 0;
  radio_b_unpressed = 0;
  radio_b_repeated = 0;
  radio_c_pressed = 0;
  radio_c_unpressed = 0;
  radio_c_repeated = 0;
  radio_d_pressed = 0;
  radio_d_unpressed = 0;
  radio_d_repeated = 0;

  //Button MODE
  if (!HAL_GPIO_ReadPin(BUT_MODE_GPIO_Port, BUT_MODE_Pin)) {
    if (button_mode < BUTTON_RANGE) button_mode++;
    if (button_mode == 0) {
      button_mode_pressed = 1;
      button_mode_hold = 1;
      button_mode = BUTTON_RANGE;
    }
    if (button_mode == BUTTON_RANGE) {
      if (button_mode_repeat-- <= 0) {
        button_mode_repeated = 1;
        button_mode_repeat = BUTTON_REPEAT_PERIOD;
      }
    }
  } else {
    if (button_mode > -BUTTON_RANGE) button_mode--;
    if (button_mode == 0) {
      button_mode_unpressed = 1;
      button_mode_hold = 0;
      button_mode = -BUTTON_RANGE;
      button_mode_repeat = BUTTON_REPEAT_DELAY;
    }
  }

  //Button UP/START
  if (!HAL_GPIO_ReadPin(BUT_UP_GPIO_Port, BUT_UP_Pin)) {
    if (button_up < BUTTON_RANGE) button_up++;
    if (button_up == 0) {
      button_up_pressed = 1;
      button_up_hold = 1;
      button_up = BUTTON_RANGE;
    }
    if (button_up == BUTTON_RANGE) {
      if (button_up_repeat-- <= 0) {
        button_up_repeated = 1;
        button_up_repeat = BUTTON_REPEAT_PERIOD;
      }
    }
  } else {
    if (button_up > -BUTTON_RANGE) button_up--;
    if (button_up == 0) {
      button_up_unpressed = 1;
      button_up_hold = 0;
      button_up = -BUTTON_RANGE;
      button_up_repeat = BUTTON_REPEAT_DELAY;
    }
  }

  //Button DOWN/FINISH
  if (!HAL_GPIO_ReadPin(BUT_DOWN_GPIO_Port, BUT_DOWN_Pin)) {
    if (button_down < BUTTON_RANGE) button_down++;
    if (button_down == 0) {
      button_down_pressed = 1;
      button_down_hold = 1;
      button_down = BUTTON_RANGE;
    }
    if (button_down == BUTTON_RANGE) {
      if (button_down_repeat-- <= 0) {
        button_down_repeated = 1;
        button_down_repeat = BUTTON_REPEAT_PERIOD;
      }
    }
  } else {
    if (button_down > -BUTTON_RANGE) button_down--;
    if (button_down == 0) {
      button_down_unpressed = 1;
      button_down_hold = 0;
      button_down = -BUTTON_RANGE;
      button_down_repeat = BUTTON_REPEAT_DELAY;
    }
  }

  //Radio A button (UP/START)
  if (HAL_GPIO_ReadPin(RADIO_D1_GPIO_Port, RADIO_D1_Pin)) {
    if (radio_a < RADIO_RANGE) radio_a++;
    if (radio_a == 0) {
      radio_a_pressed = 1;
      radio_a_hold = 1;
      radio_a = RADIO_RANGE;
    }
    if (radio_a == RADIO_RANGE) {
      if (radio_a_repeat-- <= 0) {
        radio_a_repeated = 1;
        radio_a_repeat = BUTTON_REPEAT_PERIOD;
      }
    }
  } else {
    if (radio_a > -RADIO_RANGE) radio_a--;
    if (radio_a == 0) {
      radio_a_unpressed = 1;
      radio_a_hold = 0;
      radio_a = -RADIO_RANGE;
      radio_a_repeat = BUTTON_REPEAT_DELAY;
    }
  }

  //Radio B button (MODE)
  if (HAL_GPIO_ReadPin(RADIO_D0_GPIO_Port, RADIO_D0_Pin)) {
    if (radio_b < RADIO_RANGE) radio_b++;
    if (radio_b == 0) {
      radio_b_pressed = 1;
      radio_b_hold = 1;
      radio_b = RADIO_RANGE;
    }
    if (radio_b == RADIO_RANGE) {
      if (radio_b_repeat-- <= 0) {
        radio_b_repeated = 1;
        radio_b_repeat = BUTTON_REPEAT_PERIOD;
      }
    }
  } else {
    if (radio_b > -RADIO_RANGE) radio_b--;
    if (radio_b == 0) {
      radio_b_unpressed = 1;
      radio_b_hold = 0;
      radio_b = -RADIO_RANGE;
      radio_b_repeat = BUTTON_REPEAT_DELAY;
    }
  }

  //Radio C button (DOWN/FINISH)
  if (HAL_GPIO_ReadPin(RADIO_D2_GPIO_Port, RADIO_D2_Pin)) {
    if (radio_c < RADIO_RANGE) radio_c++;
    if (radio_c == 0) {
      radio_c_pressed = 1;
      radio_c_hold = 1;
      radio_c = RADIO_RANGE;
    }
    if (radio_c == RADIO_RANGE) {
      if (radio_c_repeat-- <= 0) {
        radio_c_repeated = 1;
        radio_c_repeat = BUTTON_REPEAT_PERIOD;
      }
    }
  } else {
    if (radio_c > -RADIO_RANGE) radio_c--;
    if (radio_c == 0) {
      radio_c_unpressed = 1;
      radio_c_hold = 0;
      radio_c = -RADIO_RANGE;
      radio_c_repeat = BUTTON_REPEAT_DELAY;
    }
  }

  //Radio D button
  if (HAL_GPIO_ReadPin(RADIO_D3_GPIO_Port, RADIO_D3_Pin)) {
    if (radio_d < RADIO_RANGE) radio_d++;
    if (radio_d == 0) {
      radio_d_pressed = 1;
      radio_d_hold = 1;
      radio_d = RADIO_RANGE;
    }
    if (radio_d == RADIO_RANGE) {
      if (radio_d_repeat-- <= 0) {
        radio_d_repeated = 1;
        radio_d_repeat = BUTTON_REPEAT_PERIOD;
      }
    }
  } else {
    if (radio_d > -RADIO_RANGE) radio_d--;
    if (radio_d == 0) {
      radio_d_unpressed = 1;
      radio_d_hold = 0;
      radio_d = -RADIO_RANGE;
      radio_d_repeat = BUTTON_REPEAT_DELAY;
    }
  }
}

void show_clock(uint8_t Buf[]) {
  p10_clrscr();
  if (Buf[2] >> 4 > 0) p10_putnumber(0,  Buf[2] >> 4, 0);
  p10_putnumber(10, Buf[2] & 0x0F, 0);
  p10_putnumber(23, Buf[1] >> 4, 0);
  p10_putnumber(33, Buf[1] & 0x0F, 0);
  p10_putnumber(46, Buf[0] >> 4 & 0x0F, 0);
  p10_putnumber(56, Buf[0] & 0x0F, 0);

  p10_putrect(19, 4, 3, 2, 1);
  p10_putrect(19, 10, 3, 2, 1);
  p10_putrect(42, 4, 3, 2, 1);
  p10_putrect(42, 10, 3, 2, 1);
}

void show_time(int time) {
  p10_clrscr();
  time = time / 100;
  p10_putnumber(56, time % 10, 0);
  p10_putnumber(46, time % 60 / 10, 0);
  time = time / 60;
  p10_putnumber(33, time % 10, 0);
  p10_putnumber(23, time % 60 / 10, 0);
  time = time / 60;
  p10_putnumber(10, time % 10, 0);
  if (time >= 10) p10_putnumber(0,  time /10 % 10, 0);

  p10_putrect(19, 4, 3, 2, 1);
  p10_putrect(19, 10, 3, 2, 1);
  p10_putrect(42, 4, 3, 2, 1);
  p10_putrect(42, 10, 3, 2, 1);
}

void show_time_0(int time) {
  p10_clrscr();
  time = time / 10;
  p10_putnumber(46, time % 10, 0);
  time = time / 10;
  p10_putnumber(33, time % 10, 0);
  p10_putnumber(23, time % 60 / 10, 0);
  time = time / 60;
  p10_putnumber(10, time % 10, 0);
  time = time / 10;
  if (time > 0) p10_putnumber(0, time % 10, 0);
  p10_putrect(19, 4, 3, 2, 1);
  p10_putrect(19, 10, 3, 2, 1);
  p10_putrect(42, 14, 3, 2, 1);
}

void show_time_00(int time) {
  p10_clrscr();
  p10_putnumber(56, time % 10, 0);
  time = time / 10;
  p10_putnumber(46, time % 10, 0);
  time = time / 10;
  p10_putnumber(33, time % 10, 0);
  p10_putnumber(23, time % 60 / 10, 0);
  time = time / 60;
  p10_putnumber(10, time % 10, 0);
  time = time / 10;
  if (time > 0) p10_putnumber(0, time % 10, 0);
  p10_putrect(19, 4, 3, 2, 1);
  p10_putrect(19, 10, 3, 2, 1);
  p10_putrect(42, 14, 3, 2, 1);
}

void show_timer3(int time) {
  p10_clrscr();

  if (time <= -1*60*60*100) {
    p10_putrect(1, 7, 6, 2, 1);
  } else if (time <= -10*60*100) {
    p10_putrect(14, 7, 6, 2, 1);
  } else if (time < 0) {
    p10_putrect(24, 7, 6, 2, 1);
  }
  if (time < 0) {
    time = 99 - time;
  }

  time = time / 100;
  p10_putnumber(56, time % 10, 0);
  time = time / 10;
  p10_putnumber(46, time % 6, 0);
  p10_putrect(42, 4, 3, 2, 1);
  p10_putrect(42, 10, 3, 2, 1);
  time = time / 6;
  p10_putnumber(33, time % 10, 0);
  time = time / 10;
  if (time <= 0) return;
  p10_putnumber(23, time % 6, 0);
  time = time / 6;
  if (time <= 0) return;
  p10_putrect(19, 4, 3, 2, 1);
  p10_putrect(19, 10, 3, 2, 1);
  p10_putnumber(10, time % 10, 0);
  time = time / 10;
  if (time <= 0) return;
  p10_putnumber(0, time % 10, 0);
}

void show_timer3_setup(int time, int start_time, int mode, int blink) {
  p10_putscreen(p10_timer3_setup);

  if (!blink) mode = 0;
  //момант старту
  start_time /= 100;
  if (mode != 3) p10_putnumber4x7(60, 0, start_time % 10, 0);
  start_time /= 10;
  if (mode != 3) p10_putnumber4x7(55, 0, start_time % 6, 0);
  p10_setxy(53, 2, 1);
  p10_setxy(53, 4, 1);
  start_time /= 6;
  if (mode != 4) p10_putnumber4x7(48, 0, start_time % 10, 0);
  start_time /= 10;
  if (mode != 4) p10_putnumber4x7(43, 0, start_time % 6, 0);
  p10_setxy(41, 2, 1);
  p10_setxy(41, 4, 1);
  start_time /= 6;
  if (mode != 5) p10_putnumber4x7(36, 0, start_time % 10, 0);
  start_time /= 10;
  if (start_time > 0) if (mode != 5) p10_putnumber4x7(31, 0, start_time % 10, 0);

  //таймер
  if (time <= -1*60*60*100) {
    p10_putrect(32, 12, 3, 1, 1);
  } else if (time <= -10*60*100) {
    p10_putrect(39, 12, 3, 1, 1);
  } else if (time < 0) {
    p10_putrect(44, 12, 3, 1, 1);
  }
  if (time < 0) {
    time = 99 - time;
  }

  time /= 100;
  p10_putnumber4x7(60, 9, time % 10, 0);
  time /= 10;
  p10_putnumber4x7(55, 9, time % 6, 0);
  p10_setxy(53, 11, 1);
  p10_setxy(53, 13, 1);
  time /= 6;
  p10_putnumber4x7(48, 9, time % 10, 0);
  time /= 10;
  if (time <= 0) return;
  p10_putnumber4x7(43, 9, time % 6, 0);
  time /= 6;
  if (time <= 0) return;
  p10_setxy(41, 11, 1);
  p10_setxy(41, 13, 1);
  p10_putnumber4x7(36, 9, time % 10, 0);
  time /= 10;
  if (time <= 0) return;
  p10_putnumber4x7(31, 9, time % 10, 0);
}

void show_numbers(uint8_t Buf[], int number, int trafic) {
  p10_clrscr();
  if (number >= 100) p10_putint(28, number, 0);
  else if (number >= 10) p10_putint(23, number, 0);
  else p10_putint(18, number, 0);

  if (Buf[2] >> 4 > 0) p10_putnumber4x7(31, 0, Buf[2] >> 4, 0);
  p10_putnumber4x7(36, 0, Buf[2] & 0x0F, 0);
  p10_putnumber4x7(43, 0, Buf[1] >> 4, 0);
  p10_putnumber4x7(48, 0, Buf[1] & 0x0F, 0);
  p10_putnumber4x7(55, 0, Buf[0] >> 4 & 0x0F, 0);
  p10_putnumber4x7(60, 0, Buf[0] & 0x0F, 0);

  p10_setxy(41, 2, 1);
  p10_setxy(41, 4, 1);
  p10_setxy(53, 2, 1);
  p10_setxy(53, 4, 1);

  if (trafic > 0) {
    for (int i = 1; i <= 5; i++) {
      p10_putsprite(65 - 7 * i, 10, 6, 6, (trafic < i) ? p10_sprite1 : p10_sprite2, 1);
    }
  } else if (trafic == 0) {
    p10_putsprite(38, 9, 32, 7, p10_sprite_start, 1);
  }
}

void show_count(int left, int right) {
  p10_clrscr();
  p10_putint(29, left, 0);
  p10_putint(34 + p10_intwidth(right), right, 0);
  p10_putrect(31, 4, 3, 2, 1);
  p10_putrect(31, 10, 3, 2, 1);
}

int buzzer_timer = 0;
void buzzer(int prescaler, int duration) {
  __HAL_TIM_SET_PRESCALER(&htim2, prescaler);
  HAL_TIM_PWM_Start(&htim2, TIM_CHANNEL_2);
  buzzer_timer = duration;
}
void buzzer_off() {
  if (buzzer_timer > 0) {
    buzzer_timer--;
    if (buzzer_timer == 0) {
      HAL_TIM_PWM_Stop(&htim2, TIM_CHANNEL_2);
    }
  }
}

void asd(int v1, int v2) {
  p10_putint4x7(64, 0, v1, 0);
  p10_putint4x7(64, 8, v2, 0);
  p10_flip();
  HAL_Delay(5000);
}

uint8_t TimeBuf[4];

void main_loop() {
  uint8_t Time[3];
  uint8_t last_second = 0xFF;
  int loop_cnt = 0;
  int last_loop_cnt = 0;
  int time = 0;
  int second = 0;
  int subsecond = 0;
  int last_subsecond = -1;
  int program = PROGRAM_CLOCK;
  int mode = 0;
  int mode_back = 0;
  int t3_time = 0;
  int t3_start_time = -1;
  int sw_state = SW_READY;
  int sw_time = 0;
  int sw_start_time = -1;
  int number = 0;
  int refresh = 1;
  int brightness_freeze = 0;
  int blink_freeze = 0;
  int interval_second = 0;
  int sw_start = 0;
  int sw_precision = 2;
  int sw_sound = 0;
  int count_left = 0;
  int count_right = 0;
  int count_left_changed = 0;
  int count_right_changed = 0;

//  p10_putscreen(p10_start);
//  p10_flip();
//  HAL_Delay(1000);

  //наладкі з памяці
  uint8_t buf[8];
  buf[0] = 0x05;
  HAL_I2C_Master_Transmit(&hi2c1, DEV_ADDR, buf, 1, 1000);
  HAL_Delay(5);
  HAL_I2C_Master_Receive(&hi2c1, DEV_ADDR, buf, 2, 1000);
  program = buf[1] & 0b00000111;
  if (program >= PROGRAM_CNT) program = PROGRAM_CLOCK;
  sw_start = buf[1] >> 3 & 0b00000011;
  sw_precision = buf[1] >> 5 & 0b00000011;
  if (sw_precision > 2) sw_precision = 2;
  sw_sound = buf[1] >> 7 & 0b00000001;

  while (1) {
    int second_changed = 0;
    int subsecond_changed = 0;

    //Get Time
    Time[0] = 0;
    HAL_I2C_Master_Transmit_IT(&hi2c1, DEV_ADDR, Time, 1);
    HAL_Delay(5); //каб не міргаў
    memcpy(Time, TimeBuf, 3);

    loop_cnt++;
    if (last_second != Time[0]) {
      last_second = Time[0];
      last_loop_cnt = loop_cnt;
      loop_cnt = 0;
      second = BCDToInt(Time[2]) * 60 * 60 + BCDToInt(Time[1]) * 60 + BCDToInt(Time[0]);
      second_changed = 1;
    }
    if (last_loop_cnt > 0) {
      subsecond = loop_cnt * 10 / last_loop_cnt;
      if (subsecond > 9) subsecond = 9;
    }
    if (last_subsecond != subsecond) {
      last_subsecond = subsecond;
      subsecond_changed = 1;
    }
    time = BCDTimeToInt(Time, (last_loop_cnt > 0) ? loop_cnt * 100 / last_loop_cnt : 0);

    buzzer_off();
    button_filter();

    //Гук
    if (second_changed) {
      interval_second = second % signals[signal_index];

      if (program == PROGRAM_CLOCK && mode == 0 && signals[signal_index] > 0) {
        if (interval_second == 0) {
          buzzer(BUZZER_PRESCALER2, last_loop_cnt);
        } else if (interval_second + 4 - signals[signal_index] >= 0 && signals[signal_index] >= 10) {
          buzzer(BUZZER_PRESCALER1, last_loop_cnt / 3);
        }
      }

      if (program == PROGRAM_NUMBERS && mode == 0 && signals[signal_index] > 0) {
        if (interval_second == 0) {
          buzzer(BUZZER_PRESCALER2, last_loop_cnt);
        } else if (interval_second + 4 - signals[signal_index] >= 0 && signals[signal_index] >= 10) {
          buzzer(BUZZER_PRESCALER1, last_loop_cnt / 3);
        }
        if ((signals[signal_index] >= 10 && interval_second == 3)
            || (signals[signal_index] < 10 && interval_second == 1))
        {
          number++;
          if (number >= 1000) number = 0;
        }
      }
    }

//    агучванне кнопак - непрыгожа атрымліваецца
//    if (button_mode_pressed || button_up_pressed || button_down_pressed) {
//      buzzer(BUZZER_PRESCALER_BUTTON, 1);
//    }

    //Гадзіннік
    if ((program == PROGRAM_CLOCK && (mode == 0 || mode >= 3))
        || (program == PROGRAM_TIMER3 && mode== 0))
    {
      if (subsecond_changed && (subsecond == 0 || subsecond == 5)) {
        if (brightness_freeze > 0) {
          brightness_freeze--;
        }
        if (blink_freeze > 0) {
          blink_freeze--;
        }
        refresh = 1;
      }
    }

    //Нумары
    if (program == PROGRAM_NUMBERS && (mode == 0 || mode >= 4)) {
      if (second_changed || (subsecond_changed && subsecond == 5)) {
        if (blink_freeze > 0) {
          blink_freeze--;
        }
        refresh = 1;
      }
    }

    //яркасць
    if ((button_up_pressed || button_down_pressed || radio_a_pressed || radio_c_pressed)
        && ((program == PROGRAM_CLOCK && mode == 0)
            || (program == PROGRAM_STOPWATCH && mode == 2)
            || (program == PROGRAM_TIMER3 && mode == 0)
            || (program == PROGRAM_NUMBERS && mode == 3)
            || (program == PROGRAM_COUNT && mode == 2)))
    {
      if (button_up_pressed || radio_a_pressed) {
        if (brightness_index < BRIGHTNESS_STEPS - 1) brightness_index++;
      }
      if (button_down_pressed || radio_c_pressed) {
        if (brightness_index > 0) brightness_index--;
      }
      __HAL_TIM_SET_COMPARE(&htim1, TIM_CHANNEL_1, brightness[brightness_index]);
      if (mode > 0) mode_back = 1;

      p10_putscreen(p10_brightness);
      p10_putint(64, brightness[brightness_index] + 1, 0);
      p10_flip();
      if ((program == PROGRAM_CLOCK && mode == 0)
          || (program == PROGRAM_TIMER3 && mode == 0))
      {
        brightness_freeze = 2;
      }
      refresh = 1;
    }

    //Кнопка змены рэжыму (жоўтая)
    if (button_mode_pressed || radio_b_pressed) {
      mode++;
      if (mode_back) {
        mode_back = 0;
        mode = 0;
      }
      if (program == PROGRAM_CLOCK && mode > 5) mode = 0;
      if (program == PROGRAM_STOPWATCH && mode > 5) mode = 0;
      if (program == PROGRAM_TIMER3 && mode > 5) mode = 0;
      if (program == PROGRAM_NUMBERS && mode > 6) mode = 0;
      if (program == PROGRAM_COUNT && mode > 2) mode = 0;
      refresh = 1;

      if (mode == 0) {
        //Захоўваем наладкі
        uint8_t out2[4];
        out2[0] = 0x04;
        out2[1] = 0;
        out2[2] = 1;
        out2[3] = program | sw_start << 3 | sw_precision << 5 | sw_sound << 7;
        HAL_I2C_Master_Transmit(&hi2c1, DEV_ADDR, out2, 4, 1000);
        HAL_Delay(20);
      }
    }

    //пераключэнне праграмы
    if (mode == 1 && (button_up_pressed || button_down_pressed || radio_a_pressed || radio_c_pressed)) {
      program += (button_up_pressed || radio_a_pressed) ? 1 : -1;
      if (program >= PROGRAM_CNT) program = 0;
      if (program < 0) program = PROGRAM_CNT - 1;
      mode_back = 1;
      refresh = 1;
    }

    //наладка сігналу
    if ((button_up_pressed || button_up_repeated || button_down_pressed || button_down_repeated
            || radio_a_pressed || radio_a_repeated || radio_c_pressed || radio_c_repeated)
        && ((program == PROGRAM_CLOCK && mode == 2)
            || (program == PROGRAM_NUMBERS && mode == 2)
            || (program == PROGRAM_TIMER3 && mode == 2)))
    {
      if (button_up_pressed || button_up_repeated || radio_a_pressed || radio_a_repeated) {
        signal_index = MIN(signal_index + 1, SIGNAL_STEPS - 1);
      }
      if (button_down_pressed || button_down_repeated || radio_c_pressed || radio_c_repeated) {
        signal_index = MAX(signal_index - 1, 0);
      }
      mode_back = 1;
      refresh = 1;
    }

    //наладка часу
    if (((program == PROGRAM_CLOCK && mode >= 3)
        || (program == PROGRAM_NUMBERS && mode >= 4))
        && (button_up_pressed || button_up_repeated || button_down_pressed || button_down_repeated
            || radio_a_pressed || radio_a_repeated || radio_c_pressed || radio_c_repeated))
    {
      uint8_t Out[2];
      if (program == PROGRAM_CLOCK) {
        Out[0] = mode - 3;
      } else {
        Out[0] = mode - 4;
      }
      if (button_up_pressed || button_up_repeated || radio_a_pressed || radio_a_repeated) {
        switch (Out[0]) {
        case 2: Out[1] = IntToBCD((BCDToInt(Time[2]) + 1) % 24); break;
        case 1: Out[1] = IntToBCD((BCDToInt(Time[1]) + 1) % 60); break;
        case 0: Out[1] = 0; break;
        }
      }
      if (button_down_pressed || button_down_repeated || radio_c_pressed || radio_c_repeated) {
        switch (Out[0]) {
        case 2: Out[1] = IntToBCD((BCDToInt(Time[2]) + 23) % 24); break;
        case 1: Out[1] = IntToBCD((BCDToInt(Time[1]) + 59) % 60); break;
        case 0: Out[1] = IntToBCD((BCDToInt(Time[0])/10 + 1) * 10 % 60); break;
        }
      }
      HAL_I2C_Master_Transmit(&hi2c1, DEV_ADDR, Out, 2, 1000);
      last_second = 0xFF;
      blink_freeze = 3;
      continue;
    }

    //наладка спосабу старта секундамера
    if ((button_up_pressed || button_up_repeated || button_down_pressed || button_down_repeated
          || radio_a_pressed || radio_a_repeated || radio_c_pressed || radio_c_repeated)
        && (program == PROGRAM_STOPWATCH && mode == 3))
    {
      sw_start = (sw_start + ((button_up_pressed || button_up_repeated || radio_a_pressed || radio_a_repeated) ? 1 : 3)) % 4;
      mode_back = 1;
      refresh = 1;
    }

    //наладка дакладнасці секундамера
    if ((button_up_pressed || button_up_repeated || button_down_pressed || button_down_repeated
           || radio_a_pressed || radio_a_repeated || radio_c_pressed || radio_c_repeated)
        && (program == PROGRAM_STOPWATCH && mode == 4))
    {
      if (button_up_pressed || button_up_repeated || radio_a_pressed || radio_a_repeated) {
        sw_precision = sw_precision + 1;
        if (sw_precision > 2) sw_precision = 0;
      }
      if (button_down_pressed || button_down_repeated || radio_c_pressed || radio_c_repeated) {
        sw_precision = sw_precision - 1;
        if (sw_precision < 0) sw_precision = 2;
      }
      mode_back = 1;
      refresh = 1;
    }

    //наладка гуку секундамера
    if ((button_up_pressed || button_up_repeated || button_down_pressed || button_down_repeated
          || radio_a_pressed || radio_a_repeated || radio_c_pressed || radio_c_repeated)
        && (program == PROGRAM_STOPWATCH && mode == 5))
    {
      sw_sound = sw_sound ? 0 : 1;
      mode_back = 1;
      refresh = 1;
    }

    //Секундамер - старт (аўта зброс, перазапуск пасля паўзы, перазапуск пасля спліта)
    if (((button_up_pressed || radio_a_pressed) && program == PROGRAM_STOPWATCH && mode == 0 && sw_start != 1)
        || ((button_up_unpressed || radio_a_unpressed) && program == PROGRAM_STOPWATCH && mode == 0 && sw_start == 1))
    {
      if (sw_state == SW_READY) {
        sw_start_time = time;
        sw_time = 0;
        sw_state = SW_STARTED;
        if (sw_state == SW_STARTED && sw_sound) buzzer(BUZZER_PRESCALER1, last_loop_cnt / 3);
      } else if (sw_state == SW_STOPPED) {
        if (sw_start <= 1) {
          sw_time = 0;
        }
        if (sw_start <= 2) {
          sw_start_time = time - sw_time;
        }
        sw_state = SW_STARTED;
        if (sw_state == SW_STARTED && sw_sound) buzzer(BUZZER_PRESCALER1, last_loop_cnt / 3);
      }
    }

    //Адлік секундамера
    if (subsecond_changed && program == PROGRAM_STOPWATCH && mode == 0) {
      if (sw_state == SW_STARTED) {
        sw_time = time - sw_start_time;
        if (sw_time < 0) sw_time += 24*60*60*100;
        refresh = 1;
      }
    }

    //Секундамер - зброс
    if ((button_up_repeated || radio_a_repeated || radio_d_repeated) && program == PROGRAM_STOPWATCH && mode == 0 && sw_state != SW_READY) {
      sw_state = SW_READY;
      sw_time = 0;
      refresh = 1;
    }

    //Секундамер - стоп
    if ((button_down_pressed || radio_c_pressed) && program == PROGRAM_STOPWATCH && mode == 0 && sw_state == SW_STARTED) {
      sw_state = SW_STOPPED;
      sw_time = time - sw_start_time;
      if (sw_time < 0) sw_time += 24*60*60*100;
      refresh = 1;
      if (sw_sound) buzzer(BUZZER_PRESCALER2, last_loop_cnt);
    }

    //Адлік таймера
    if (subsecond_changed && program == PROGRAM_TIMER3) {
      t3_time = BCDTimeToInt(Time, subsecond * 10);
      if (t3_start_time < 0) {
        t3_start_time = t3_time - t3_time % (60*100) + 4*60*100;
      }
      t3_time = t3_time - t3_start_time - 24*60*60*100;
      if (t3_time <= -10*60*60*100) t3_time += 24*60*60*100;
      if (t3_time <= -10*60*60*100) t3_time += 24*60*60*100;
      if (blink_freeze > 0) blink_freeze--;
      refresh = 1;

      //Гук таймера
      if (mode == 0 && second_changed) {
        if (signals[signal_index] > 0) {
          interval_second = t3_time / 100 % signals[signal_index];
          if (interval_second > 0) interval_second -= signals[signal_index];
        } else {
          interval_second = t3_time / 100;
        }

        if (interval_second == 0) {
          buzzer(BUZZER_PRESCALER2, last_loop_cnt);
        } else if (-4 <= interval_second && interval_second <= -1 && signals[signal_index] != 5) {
          buzzer(BUZZER_PRESCALER1, last_loop_cnt / 3);
        }
      }
    }
    //Таймер. Наладка стартавага часу
    if ((program == PROGRAM_TIMER3 && mode >= 3)
        && (button_up_pressed || button_up_repeated || button_down_pressed || button_down_repeated
            || radio_a_pressed || radio_a_repeated || radio_c_pressed || radio_c_repeated))
    {
      if (button_up_pressed || button_up_repeated || radio_a_pressed || radio_a_repeated) {
        switch (mode) {
        case 3: t3_start_time += (t3_start_time / 100 % 60 < 59) ? (1*100) : (-59*100); break;
        //case 4: t3_start_time += (t3_start_time / (60*100) % 60 < 59) ? (1*60*100) : (-59*60*100); break;
        case 4: t3_start_time = (t3_start_time + 1*60*100) % (24*60*60*100); break;
        case 5: t3_start_time += (t3_start_time / (60*60*100) % 24 < 23) ? (1*60*60*100) : (-23*60*60*100); break;
        }
      }
      if (button_down_pressed || button_down_repeated || radio_c_pressed || radio_c_repeated) {
        switch (mode) {
        case 3: t3_start_time += (t3_start_time / 100 % 60 > 0) ? (-1*100) : (59*100); break;
        //case 4: t3_start_time += (t3_start_time / (60*100) % 60 > 0) ? (-1*60*100) : (59*60*100); break;
        case 4: t3_start_time += (t3_start_time / (60*100) > 0) ? (-1*60*100) : ((24*60 - 1)*60*100); break;
        case 5: t3_start_time += (t3_start_time / (60*60*100) % 24 > 0) ? (-1*60*60*100) : (23*60*60*100); break;
        }
      }
      refresh = 1;
      blink_freeze = 6;
      continue;
    }

    //нумары
    if (program == PROGRAM_NUMBERS && mode == 0)
    {
      if (button_up_pressed || button_up_repeated || radio_a_pressed || radio_a_repeated) {
        number++;
        if (number >= 1000) number = 0;
        refresh = 1;
      }
      if (button_down_pressed || button_down_repeated || radio_c_pressed || radio_c_repeated) {
        number--;
        if (number < 0) number = 999;
        refresh = 1;
      }
      if ((button_up_hold && button_down_hold) || radio_d_repeated) {
        number = 0;
        refresh = 1;
      }
    }

    //Лік гульні
    if (program == PROGRAM_COUNT && mode == 0)
    {
      if (button_up_unpressed || radio_a_unpressed) {
        if (count_left_changed) {
          count_left_changed = 0;
        } else {
          count_left++;
          refresh = 1;
        }
      }
      if ((button_up_repeated || radio_a_repeated) && !count_left_changed) {
        count_left--;
        count_left_changed = 1;
        refresh = 1;
      }

      if (button_down_unpressed || radio_c_unpressed) {
        if (count_right_changed) {
          count_right_changed = 0;
        } else {
          count_right++;
          refresh = 1;
        }
      }
      if ((button_down_repeated || radio_c_repeated) && !count_right_changed) {
        count_right--;
        count_right_changed = 1;
        refresh = 1;
      }

      if (button_up_hold && button_down_hold) {
        count_left = 0;
        count_right = 0;
        count_left_changed = 1;
        count_right_changed = 1;
        refresh = 1;
      }
      if (radio_d_repeated) {
        count_left = 0;
        count_right = 0;
        refresh = 1;
      }
    }

    //view
    if (refresh) {
      refresh = 0;

      //Гадзіннік
      if (program == PROGRAM_CLOCK && mode == 0 && brightness_freeze == 0) {
        show_clock(Time);
      }
      else if (program == PROGRAM_CLOCK && mode >= 3) {
        show_clock(Time);
        if (subsecond >= 5 && blink_freeze == 0) {
          p10_putrect((5 - mode) * 23, 0, 18, 16, 0);
        }
      }

      //Нумары
      else if (program == PROGRAM_NUMBERS && mode == 0) {
        if (signals[signal_index] == 0) {
          show_numbers(Time, number, -1);
        } else {
          if (interval_second < 1 || (signals[signal_index] >= 10 && interval_second < 3)) {
            show_numbers(Time, number, 0);
          } else if (signals[signal_index] - interval_second <= 5) {
            show_numbers(Time, number, signals[signal_index] - interval_second);
          } else {
            show_numbers(Time, number, -1);
          }
        }
      }
      else if (program == PROGRAM_NUMBERS && mode >= 4) {
        show_numbers(Time, number, -1);
        if (subsecond >= 5 && blink_freeze == 0) {
          p10_putrect((6 - mode) * 12 + 31, 0, 9, 7, 0);
        }
      }

      //Яркасць
      else if ((program == PROGRAM_CLOCK && mode == 0 && brightness_freeze > 0)
          || (program == PROGRAM_STOPWATCH && mode == 2)
          || (program == PROGRAM_TIMER3 && mode == 0 && brightness_freeze > 0)
          || (program == PROGRAM_NUMBERS && mode == 3)
          || (program == PROGRAM_COUNT && mode == 2))
      {
        p10_putscreen(p10_brightness);
        p10_putint(64, brightness[brightness_index] + 1, 0);
      }

      //Праграма
      else if (mode == 1) {
        switch (program) {
        case PROGRAM_CLOCK: p10_putscreen(p10_program_clock); break;
        case PROGRAM_STOPWATCH: p10_putscreen(p10_program_stopwatch); break;
        case PROGRAM_TIMER3: p10_putscreen(p10_program_timer3); break;
        case PROGRAM_NUMBERS: p10_putscreen(p10_program_numbers); break;
        case PROGRAM_COUNT: p10_putscreen(p10_program_count); break;
        }
      }

      //Інтэрвал / Сігнал
      else if ((program == PROGRAM_CLOCK && mode == 2)
          || (program == PROGRAM_TIMER3 && mode == 2)
          || (program == PROGRAM_NUMBERS && mode == 2))
      {
        p10_putscreen(p10_signal);
        if (signals[signal_index] != 0) {
          p10_putrect(33, 0, 32, 16, 0);
          p10_putnumber(33, signals[signal_index] / 60 % 10, 0);
          p10_putnumber(46, signals[signal_index] % 60 / 10, 0);
          p10_putnumber(56, signals[signal_index] % 10, 0);
          p10_putrect(42, 4, 3, 2, 1);
          p10_putrect(42, 10, 3, 2, 1);
        }
      }

      //view Секундамер
      else if (program == PROGRAM_STOPWATCH && mode == 0) {
        if (sw_time >= 60*60*100 || sw_precision == 0) {
          show_time(sw_time);
        } else {
          if (sw_state == SW_STOPPED && sw_precision == 2) {
            show_time_00(sw_time);
          } else {
            show_time_0(sw_time);
          }
        }
      }

      //view Таймер
      else if (program == PROGRAM_TIMER3 && mode == 0 && brightness_freeze == 0) {
        show_timer3(t3_time);
      }
      else if (program == PROGRAM_TIMER3 && mode >= 3) {
        show_timer3_setup(t3_time, t3_start_time, mode, subsecond >= 7 && blink_freeze == 0);
      }

      //view наладка спосабу старта секундамера
      else if (program == PROGRAM_STOPWATCH && mode == 3) {
        switch (sw_start) {
        case 0: p10_putscreen(p10_stopwatch_start0); break;
        case 1: p10_putscreen(p10_stopwatch_start1); break;
        case 2: p10_putscreen(p10_stopwatch_start2); break;
        case 3: p10_putscreen(p10_stopwatch_start3); break;
        }
      }

      //view наладка дакладнасці секундамера
      else if (program == PROGRAM_STOPWATCH && mode == 4) {
        p10_putscreen(p10_stopwatch_precision);
        switch (sw_precision) {
        case 0:
          p10_putnumber4x7(48, 9, 1, 0);
          p10_setxy(53, 15, 1);
          p10_putnumber4x7(55, 9, 0, 0);
          p10_putnumber4x7(60, 9, 0, 0);
          break;
        case 1:
          p10_putnumber4x7(48, 9, 0, 0);
          p10_setxy(53, 15, 1);
          p10_putnumber4x7(55, 9, 1, 0);
          p10_putnumber4x7(60, 9, 0, 0);
          break;
        case 2:
          p10_putnumber4x7(48, 9, 0, 0);
          p10_setxy(53, 15, 1);
          p10_putnumber4x7(55, 9, 0, 0);
          p10_putnumber4x7(60, 9, 1, 0);
          break;
        }
      }

      //view наладка гуку секундамера
      else if (program == PROGRAM_STOPWATCH && mode == 5) {
        if (sw_sound == 0) p10_putscreen(p10_stopwatch_sound0);
        else p10_putscreen(p10_stopwatch_sound1);
      }

      //view лік гульні
      else if (program == PROGRAM_COUNT && mode == 0) {
        show_count(count_left, count_right);
      }

      p10_flip();
    }

  }
}
/* USER CODE END 0 */

int main(void)
{

  /* MCU Configuration--------------------------------------------------------*/

  /* Reset of all peripherals, Initializes the Flash interface and the Systick. */
  HAL_Init();

  /* Configure the system clock */
  SystemClock_Config();

  /* Initialize all configured peripherals */
  MX_GPIO_Init();
  MX_DMA_Init();
  MX_I2C1_Init();
  MX_SPI2_Init();
  MX_TIM1_Init();
  MX_TIM2_Init();
  MX_TIM3_Init();
  /* USER CODE BEGIN 2 */
//  ST7789_Init();

  p10_init(&hspi2);
  HAL_TIM_Base_Start_IT(&htim1);
  HAL_TIM_OC_Start_IT(&htim1, TIM_CHANNEL_1);

  __HAL_TIM_SET_COMPARE(&htim1, TIM_CHANNEL_1, brightness[brightness_index]);

  /* USER CODE END 2 */

  /* Infinite loop */
  /* USER CODE BEGIN WHILE */
  main_loop();

  while (0)
  {
    /* USER CODE END WHILE */

  }
}

void SystemClock_Config(void)
{
  RCC_OscInitTypeDef RCC_OscInitStruct = {0};
  RCC_ClkInitTypeDef RCC_ClkInitStruct = {0};

  /** Initializes the RCC Oscillators according to the specified parameters
  * in the RCC_OscInitTypeDef structure.
  */
  RCC_OscInitStruct.OscillatorType = RCC_OSCILLATORTYPE_HSE;
  RCC_OscInitStruct.HSEState = RCC_HSE_ON;
  RCC_OscInitStruct.HSEPredivValue = RCC_HSE_PREDIV_DIV1;
  RCC_OscInitStruct.HSIState = RCC_HSI_ON;
  RCC_OscInitStruct.PLL.PLLState = RCC_PLL_ON;
  RCC_OscInitStruct.PLL.PLLSource = RCC_PLLSOURCE_HSE;
  RCC_OscInitStruct.PLL.PLLMUL = RCC_PLL_MUL9;
  if (HAL_RCC_OscConfig(&RCC_OscInitStruct) != HAL_OK)
  {
    Error_Handler();
  }

  /** Initializes the CPU, AHB and APB buses clocks
  */
  RCC_ClkInitStruct.ClockType = RCC_CLOCKTYPE_HCLK|RCC_CLOCKTYPE_SYSCLK
                              |RCC_CLOCKTYPE_PCLK1|RCC_CLOCKTYPE_PCLK2;
  RCC_ClkInitStruct.SYSCLKSource = RCC_SYSCLKSOURCE_PLLCLK;
  RCC_ClkInitStruct.AHBCLKDivider = RCC_SYSCLK_DIV1;
  RCC_ClkInitStruct.APB1CLKDivider = RCC_HCLK_DIV2;
  RCC_ClkInitStruct.APB2CLKDivider = RCC_HCLK_DIV1;

  if (HAL_RCC_ClockConfig(&RCC_ClkInitStruct, FLASH_LATENCY_2) != HAL_OK)
  {
    Error_Handler();
  }
}

static void MX_I2C1_Init(void)
{

  hi2c1.Instance = I2C1;
  hi2c1.Init.ClockSpeed = 100000;
  hi2c1.Init.DutyCycle = I2C_DUTYCYCLE_2;
  hi2c1.Init.OwnAddress1 = 0;
  hi2c1.Init.AddressingMode = I2C_ADDRESSINGMODE_7BIT;
  hi2c1.Init.DualAddressMode = I2C_DUALADDRESS_DISABLE;
  hi2c1.Init.OwnAddress2 = 0;
  hi2c1.Init.GeneralCallMode = I2C_GENERALCALL_DISABLE;
  hi2c1.Init.NoStretchMode = I2C_NOSTRETCH_DISABLE;
  if (HAL_I2C_Init(&hi2c1) != HAL_OK)
  {
    Error_Handler();
  }

}

static void MX_SPI2_Init(void)
{

  /* SPI2 parameter configuration*/
  hspi2.Instance = SPI2;
  hspi2.Init.Mode = SPI_MODE_MASTER;
  hspi2.Init.Direction = SPI_DIRECTION_2LINES;
  hspi2.Init.DataSize = SPI_DATASIZE_8BIT;
  hspi2.Init.CLKPolarity = SPI_POLARITY_LOW;
  hspi2.Init.CLKPhase = SPI_PHASE_1EDGE;
  hspi2.Init.NSS = SPI_NSS_SOFT;
  hspi2.Init.BaudRatePrescaler = SPI_BAUDRATEPRESCALER_2;
  hspi2.Init.FirstBit = SPI_FIRSTBIT_MSB;
  hspi2.Init.TIMode = SPI_TIMODE_DISABLE;
  hspi2.Init.CRCCalculation = SPI_CRCCALCULATION_DISABLE;
  hspi2.Init.CRCPolynomial = 10;
  if (HAL_SPI_Init(&hspi2) != HAL_OK)
  {
    Error_Handler();
  }

}

static void MX_TIM1_Init(void)
{

  TIM_ClockConfigTypeDef sClockSourceConfig = {0};
  TIM_MasterConfigTypeDef sMasterConfig = {0};
  TIM_OC_InitTypeDef sConfigOC = {0};
  TIM_BreakDeadTimeConfigTypeDef sBreakDeadTimeConfig = {0};

  htim1.Instance = TIM1;
  htim1.Init.Prescaler = 500-1;
  htim1.Init.CounterMode = TIM_COUNTERMODE_UP;
  htim1.Init.Period = 99;
  htim1.Init.ClockDivision = TIM_CLOCKDIVISION_DIV1;
  htim1.Init.RepetitionCounter = 0;
  htim1.Init.AutoReloadPreload = TIM_AUTORELOAD_PRELOAD_DISABLE;
  if (HAL_TIM_Base_Init(&htim1) != HAL_OK)
  {
    Error_Handler();
  }
  sClockSourceConfig.ClockSource = TIM_CLOCKSOURCE_INTERNAL;
  if (HAL_TIM_ConfigClockSource(&htim1, &sClockSourceConfig) != HAL_OK)
  {
    Error_Handler();
  }
  if (HAL_TIM_OC_Init(&htim1) != HAL_OK)
  {
    Error_Handler();
  }
  sMasterConfig.MasterOutputTrigger = TIM_TRGO_RESET;
  sMasterConfig.MasterSlaveMode = TIM_MASTERSLAVEMODE_DISABLE;
  if (HAL_TIMEx_MasterConfigSynchronization(&htim1, &sMasterConfig) != HAL_OK)
  {
    Error_Handler();
  }
  sConfigOC.OCMode = TIM_OCMODE_ACTIVE;
  sConfigOC.Pulse = 10;
  sConfigOC.OCPolarity = TIM_OCPOLARITY_HIGH;
  sConfigOC.OCNPolarity = TIM_OCNPOLARITY_HIGH;
  sConfigOC.OCFastMode = TIM_OCFAST_DISABLE;
  sConfigOC.OCIdleState = TIM_OCIDLESTATE_RESET;
  sConfigOC.OCNIdleState = TIM_OCNIDLESTATE_RESET;
  if (HAL_TIM_OC_ConfigChannel(&htim1, &sConfigOC, TIM_CHANNEL_1) != HAL_OK)
  {
    Error_Handler();
  }
  sBreakDeadTimeConfig.OffStateRunMode = TIM_OSSR_DISABLE;
  sBreakDeadTimeConfig.OffStateIDLEMode = TIM_OSSI_DISABLE;
  sBreakDeadTimeConfig.LockLevel = TIM_LOCKLEVEL_OFF;
  sBreakDeadTimeConfig.DeadTime = 0;
  sBreakDeadTimeConfig.BreakState = TIM_BREAK_DISABLE;
  sBreakDeadTimeConfig.BreakPolarity = TIM_BREAKPOLARITY_HIGH;
  sBreakDeadTimeConfig.AutomaticOutput = TIM_AUTOMATICOUTPUT_DISABLE;
  if (HAL_TIMEx_ConfigBreakDeadTime(&htim1, &sBreakDeadTimeConfig) != HAL_OK)
  {
    Error_Handler();
  }

}

static void MX_TIM2_Init(void)
{

  TIM_ClockConfigTypeDef sClockSourceConfig = {0};
  TIM_MasterConfigTypeDef sMasterConfig = {0};
  TIM_OC_InitTypeDef sConfigOC = {0};

  htim2.Instance = TIM2;
  htim2.Init.Prescaler = 365;
  htim2.Init.CounterMode = TIM_COUNTERMODE_UP;
  htim2.Init.Period = 99;
  htim2.Init.ClockDivision = TIM_CLOCKDIVISION_DIV1;
  htim2.Init.AutoReloadPreload = TIM_AUTORELOAD_PRELOAD_DISABLE;
  if (HAL_TIM_Base_Init(&htim2) != HAL_OK)
  {
    Error_Handler();
  }
  sClockSourceConfig.ClockSource = TIM_CLOCKSOURCE_INTERNAL;
  if (HAL_TIM_ConfigClockSource(&htim2, &sClockSourceConfig) != HAL_OK)
  {
    Error_Handler();
  }
  if (HAL_TIM_PWM_Init(&htim2) != HAL_OK)
  {
    Error_Handler();
  }
  sMasterConfig.MasterOutputTrigger = TIM_TRGO_RESET;
  sMasterConfig.MasterSlaveMode = TIM_MASTERSLAVEMODE_DISABLE;
  if (HAL_TIMEx_MasterConfigSynchronization(&htim2, &sMasterConfig) != HAL_OK)
  {
    Error_Handler();
  }
  sConfigOC.OCMode = TIM_OCMODE_PWM1;
  sConfigOC.Pulse = 49;
  sConfigOC.OCPolarity = TIM_OCPOLARITY_HIGH;
  sConfigOC.OCFastMode = TIM_OCFAST_DISABLE;
  if (HAL_TIM_PWM_ConfigChannel(&htim2, &sConfigOC, TIM_CHANNEL_2) != HAL_OK)
  {
    Error_Handler();
  }
  HAL_TIM_MspPostInit(&htim2);

}

static void MX_TIM3_Init(void)
{

  TIM_MasterConfigTypeDef sMasterConfig = {0};
  TIM_IC_InitTypeDef sConfigIC = {0};

  htim3.Instance = TIM3;
  htim3.Init.Prescaler = 327;
  htim3.Init.CounterMode = TIM_COUNTERMODE_UP;
  htim3.Init.Period = 65535;
  htim3.Init.ClockDivision = TIM_CLOCKDIVISION_DIV1;
  htim3.Init.AutoReloadPreload = TIM_AUTORELOAD_PRELOAD_DISABLE;
  if (HAL_TIM_IC_Init(&htim3) != HAL_OK)
  {
    Error_Handler();
  }
  sMasterConfig.MasterOutputTrigger = TIM_TRGO_RESET;
  sMasterConfig.MasterSlaveMode = TIM_MASTERSLAVEMODE_DISABLE;
  if (HAL_TIMEx_MasterConfigSynchronization(&htim3, &sMasterConfig) != HAL_OK)
  {
    Error_Handler();
  }
  sConfigIC.ICPolarity = TIM_INPUTCHANNELPOLARITY_RISING;
  sConfigIC.ICSelection = TIM_ICSELECTION_DIRECTTI;
  sConfigIC.ICPrescaler = TIM_ICPSC_DIV1;
  sConfigIC.ICFilter = 0;
  if (HAL_TIM_IC_ConfigChannel(&htim3, &sConfigIC, TIM_CHANNEL_1) != HAL_OK)
  {
    Error_Handler();
  }

}

static void MX_DMA_Init(void)
{

  /* DMA controller clock enable */
  __HAL_RCC_DMA1_CLK_ENABLE();

  /* DMA interrupt init */
  /* DMA1_Channel5_IRQn interrupt configuration */
  HAL_NVIC_SetPriority(DMA1_Channel5_IRQn, 3, 0);
  HAL_NVIC_EnableIRQ(DMA1_Channel5_IRQn);

}

static void MX_GPIO_Init(void)
{
  GPIO_InitTypeDef GPIO_InitStruct = {0};

  /* GPIO Ports Clock Enable */
  __HAL_RCC_GPIOC_CLK_ENABLE();
  __HAL_RCC_GPIOD_CLK_ENABLE();
  __HAL_RCC_GPIOA_CLK_ENABLE();
  __HAL_RCC_GPIOB_CLK_ENABLE();

  /*Configure GPIO pin Output Level */
  HAL_GPIO_WritePin(LED13_GPIO_Port, LED13_Pin, GPIO_PIN_RESET);

  /*Configure GPIO pin Output Level */
  HAL_GPIO_WritePin(GPIOA, ST7789_DC_Pin|P10_A_Pin|P10_B_Pin|P10_L_Pin
                          |P10_OE_Pin, GPIO_PIN_RESET);

  /*Configure GPIO pin Output Level */
  HAL_GPIO_WritePin(GPIOB, ST7789_RST_Pin|LED1_Pin|LED2_Pin, GPIO_PIN_RESET);

  /*Configure GPIO pin : LED13_Pin */
  GPIO_InitStruct.Pin = LED13_Pin;
  GPIO_InitStruct.Mode = GPIO_MODE_OUTPUT_PP;
  GPIO_InitStruct.Pull = GPIO_NOPULL;
  GPIO_InitStruct.Speed = GPIO_SPEED_FREQ_LOW;
  HAL_GPIO_Init(LED13_GPIO_Port, &GPIO_InitStruct);

  /*Configure GPIO pins : ST7789_DC_Pin P10_A_Pin P10_B_Pin P10_L_Pin
                           P10_OE_Pin */
  GPIO_InitStruct.Pin = ST7789_DC_Pin|P10_A_Pin|P10_B_Pin|P10_L_Pin
                          |P10_OE_Pin;
  GPIO_InitStruct.Mode = GPIO_MODE_OUTPUT_PP;
  GPIO_InitStruct.Pull = GPIO_NOPULL;
  GPIO_InitStruct.Speed = GPIO_SPEED_FREQ_LOW;
  HAL_GPIO_Init(GPIOA, &GPIO_InitStruct);

  /*Configure GPIO pins : RADIO_D0_Pin RADIO_D1_Pin RADIO_D2_Pin RADIO_D3_Pin */
  GPIO_InitStruct.Pin = RADIO_D0_Pin|RADIO_D1_Pin|RADIO_D2_Pin|RADIO_D3_Pin;
  GPIO_InitStruct.Mode = GPIO_MODE_INPUT;
  GPIO_InitStruct.Pull = GPIO_PULLDOWN;
  HAL_GPIO_Init(GPIOA, &GPIO_InitStruct);

  /*Configure GPIO pins : ST7789_RST_Pin LED1_Pin LED2_Pin */
  GPIO_InitStruct.Pin = ST7789_RST_Pin|LED1_Pin|LED2_Pin;
  GPIO_InitStruct.Mode = GPIO_MODE_OUTPUT_PP;
  GPIO_InitStruct.Pull = GPIO_NOPULL;
  GPIO_InitStruct.Speed = GPIO_SPEED_FREQ_LOW;
  HAL_GPIO_Init(GPIOB, &GPIO_InitStruct);

  /*Configure GPIO pins : BUT_MODE_Pin BUT_DOWN_Pin BUT_UP_Pin */
  GPIO_InitStruct.Pin = BUT_MODE_Pin|BUT_DOWN_Pin|BUT_UP_Pin;
  GPIO_InitStruct.Mode = GPIO_MODE_INPUT;
  GPIO_InitStruct.Pull = GPIO_PULLUP;
  HAL_GPIO_Init(GPIOB, &GPIO_InitStruct);

  /*Configure GPIO pin : BUTTON_Pin */
  GPIO_InitStruct.Pin = BUTTON_Pin;
  GPIO_InitStruct.Mode = GPIO_MODE_INPUT;
  GPIO_InitStruct.Pull = GPIO_NOPULL;
  HAL_GPIO_Init(BUTTON_GPIO_Port, &GPIO_InitStruct);

  /*Configure GPIO pin : DS3231_SQW_Pin */
  GPIO_InitStruct.Pin = DS3231_SQW_Pin;
  GPIO_InitStruct.Mode = GPIO_MODE_IT_RISING;
  GPIO_InitStruct.Pull = GPIO_NOPULL;
  HAL_GPIO_Init(DS3231_SQW_GPIO_Port, &GPIO_InitStruct);

}

/* USER CODE BEGIN 4 */

void Test_P10() {
//  uint8_t buf[16] = {0,0,0,0,255,255,255,255,0,0,0,0,255,255,255,255};
  uint8_t buf[] = {0x00, 0xF0,0xFF,0x0F,0xFF, 255,255,255,255, 255,255,255,255, 255,255,255,0xEF};

  HAL_GPIO_WritePin(P10_OE_GPIO_Port, P10_OE_Pin, GPIO_PIN_RESET);
  HAL_Delay(1000);

  while(1) {
    HAL_GPIO_TogglePin(LED1_GPIO_Port, LED1_Pin);

    for (uint8_t a = 0; a <= 1; a++) {
      for (uint8_t b = 0; b <= 1; b++) {
        memset(buf, 0xFF, 16);
        buf[14] = 0xFD;
        buf[15] = 0xFE;
        HAL_SPI_Transmit(&hspi2, buf, 16, 100);
        HAL_GPIO_WritePin(P10_OE_GPIO_Port, P10_OE_Pin, GPIO_PIN_RESET);

        HAL_GPIO_WritePin(P10_A_GPIO_Port, P10_A_Pin, a);
        HAL_GPIO_WritePin(P10_B_GPIO_Port, P10_B_Pin, b);

        HAL_GPIO_WritePin(P10_L_GPIO_Port, P10_L_Pin, GPIO_PIN_SET);
        HAL_GPIO_WritePin(P10_L_GPIO_Port, P10_L_Pin, GPIO_PIN_RESET);

        HAL_GPIO_WritePin(P10_OE_GPIO_Port, P10_OE_Pin, GPIO_PIN_SET);

        HAL_Delay(1);
        HAL_GPIO_WritePin(P10_OE_GPIO_Port, P10_OE_Pin, GPIO_PIN_RESET);
        HAL_Delay(2);
      }
    }
  }
}

void HAL_I2C_MasterTxCpltCallback(I2C_HandleTypeDef *hi2c)
{
  HAL_I2C_Master_Receive_IT(&hi2c1, DEV_ADDR, TimeBuf, 3);
}
void HAL_I2C_MasterRxCpltCallback(I2C_HandleTypeDef *hi2c)
{
  // I2C data ready!
}

void HAL_TIM_PeriodElapsedCallback(TIM_HandleTypeDef *htim)
{
  p10_tick();
}
void HAL_TIM_OC_DelayElapsedCallback(TIM_HandleTypeDef *htim)
{
  p10_tock();
}

/* USER CODE END 4 */

void Error_Handler(void)
{
}
